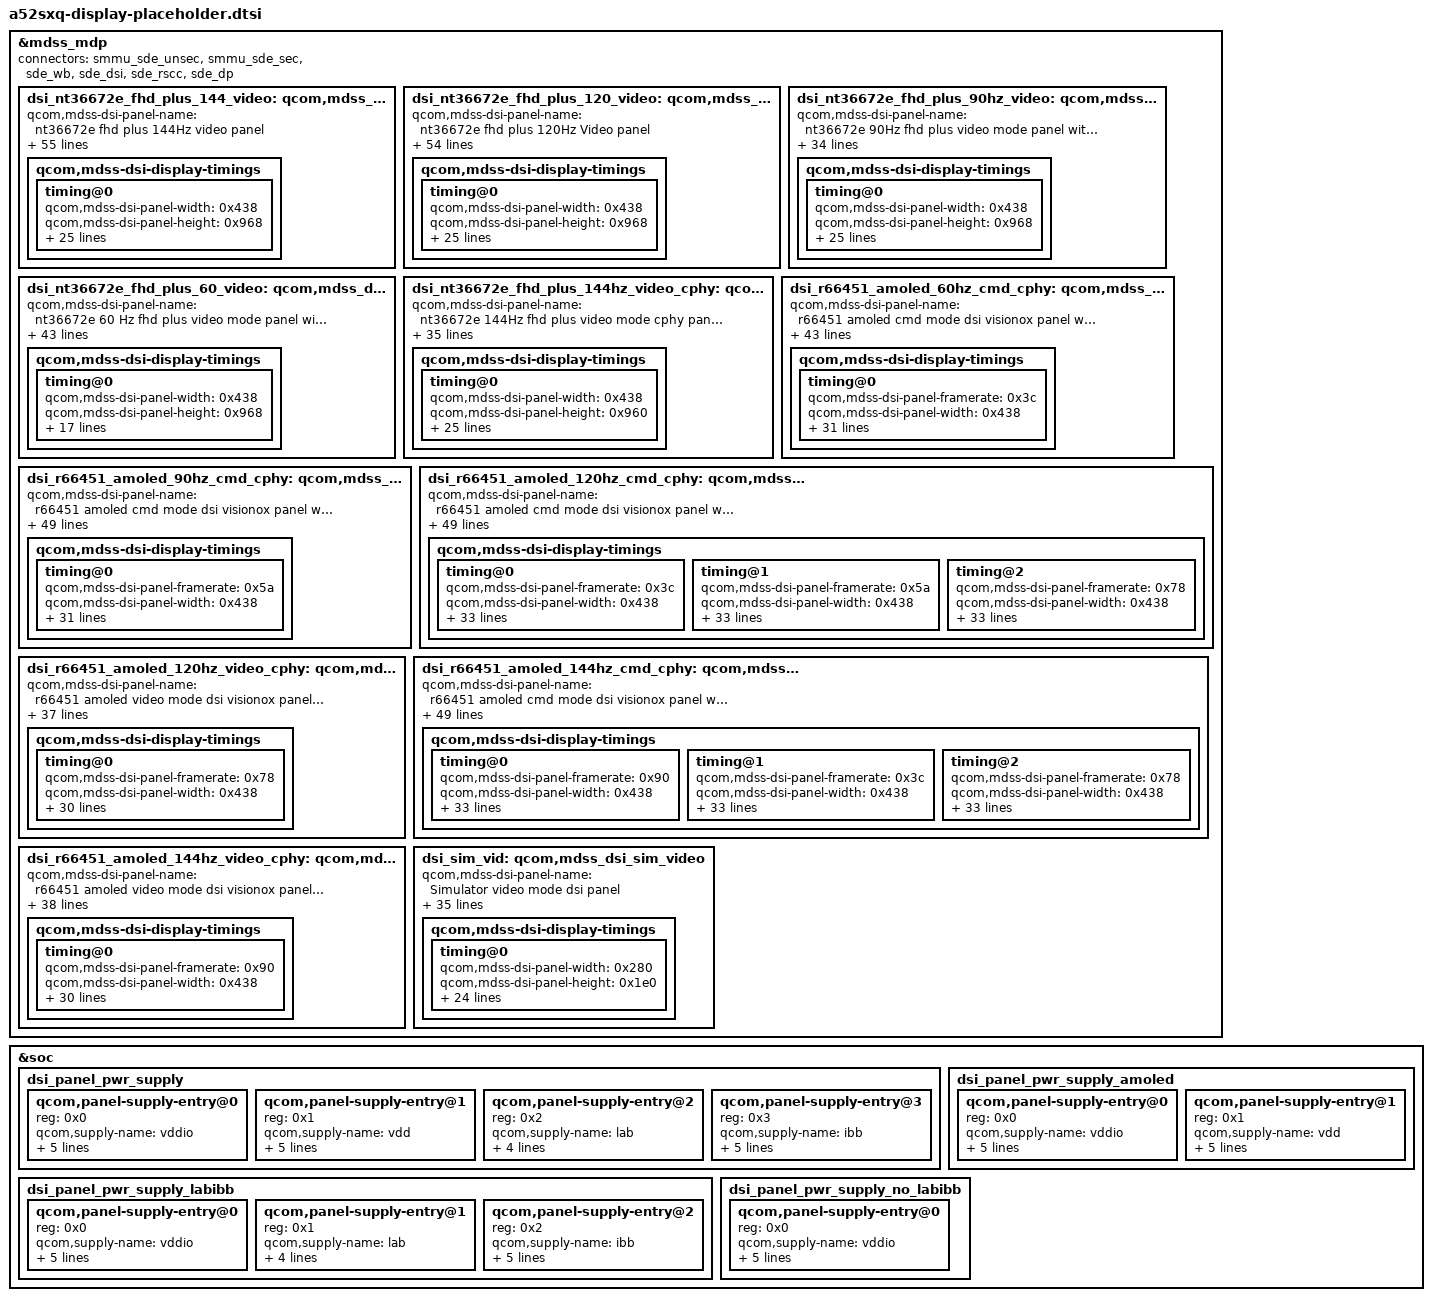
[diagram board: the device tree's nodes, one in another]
// SPDX-License-Identifier: GPL-2.0
/*
 * a52sxq board description for the Qualcomm 6.12 yupik base: display (owned by agent 'display': TODO-binding placeholder)
 * GENERATED by tools/gen.py from the phone's stock dtbo (5.4 bindings, values verbatim).
 * Do not edit: hand-written 6.12 changes live in a52sxq-bsp612-fixups.dtsi.
 */

&mdss_mdp {	/* TODO-binding: label not in the 6.12 base, placeholder */
	#cooling-cells = <0x2>;
	connectors = <&smmu_sde_unsec &smmu_sde_sec &sde_wb &sde_dsi &sde_rscc &sde_dp>;

	dsi_nt36672e_fhd_plus_144_video: qcom,mdss_dsi_nt36672e_fhd_plus_144_video {
		qcom,mdss-dsi-panel-name = "nt36672e fhd plus 144Hz video panel";
		qcom,mdss-dsi-panel-type = "dsi_video_mode";
		qcom,dsi-ctrl-num = <0x0>;
		qcom,dsi-phy-num = <0x0>;
		qcom,mdss-dsi-virtual-channel-id = <0x0>;
		qcom,mdss-dsi-stream = <0x0>;
		qcom,mdss-dsi-bpp = <0x18>;
		qcom,mdss-dsi-border-color = <0x0>;
		qcom,mdss-dsi-traffic-mode = "burst_mode";
		qcom,mdss-dsi-bllp-power-mode;
		qcom,mdss-dsi-bllp-eof-power-mode;
		qcom,mdss-dsi-lane-0-state;
		qcom,mdss-dsi-lane-1-state;
		qcom,mdss-dsi-lane-2-state;
		qcom,mdss-dsi-lane-3-state;
		qcom,mdss-dsi-dma-trigger = "trigger_sw";
		qcom,mdss-dsi-mdp-trigger = "none";
		qcom,mdss-dsi-reset-sequence = <0x1 0xa 0x0 0xa 0x1 0xa>;
		qcom,mdss-dsi-tx-eot-append;
		qcom,adjust-timer-wakeup-ms = <0x1>;
		qcom,mdss-dsi-panel-hdr-enabled;
		qcom,mdss-dsi-panel-hdr-color-primaries = <0x3a98 0x3e80 0x83d6 0x3db8 0x33c2 0x8692 0x1d4c 0xbb8>;
		qcom,mdss-dsi-panel-peak-brightness = <0x626b50>;
		qcom,mdss-dsi-panel-blackness-level = <0x1361>;
		qcom,dsi-select-clocks = "mux_byte_clk0", "mux_pixel_clk0", "src_byte_clk0", "src_pixel_clk0", "shadow_byte_clk0", "shadow_pixel_clk0";
		qcom,dsi-supported-dfps-list = <0x90 0x78 0x3c 0x30>;
		qcom,mdss-dsi-pan-enable-dynamic-fps;
		qcom,mdss-dsi-pan-fps-update = "dfps_immediate_porch_mode_vfp";
		qcom,mdss-dsi-qsync-min-refresh-rate = <0x30>;
		qcom,dsi-dyn-clk-enable;
		qcom,dsi-dyn-clk-list = <0x38d2d480 0x386dcf78 0x38a05200>;
		qcom,dsi-dyn-clk-type = "constant-fps-adjust-vfp";
		qcom,esd-check-enabled;
		qcom,mdss-dsi-panel-status-check-mode = "reg_read";
		qcom,mdss-dsi-panel-status-command = <0x6010001 0x10a>;
		qcom,mdss-dsi-panel-status-command-state = "dsi_lp_mode";
		qcom,mdss-dsi-panel-status-value = <0x9c>;
		qcom,mdss-dsi-panel-status-read-length = <0x1>;
		qcom,panel-supply-entries = <&dsi_panel_pwr_supply_labibb>;
		qcom,mdss-dsi-bl-pmic-control-type = "bl_ctrl_wled";
		qcom,mdss-dsi-bl-min-level = <0x1>;
		qcom,mdss-dsi-bl-max-level = <0xfff>;
		qcom,platform-reset-gpio = <&tlmm 0x2c 0x0>;

		qcom,mdss-dsi-display-timings {

			timing@0 {
				qcom,mdss-dsi-panel-width = <0x438>;
				qcom,mdss-dsi-panel-height = <0x968>;
				qcom,mdss-dsi-h-front-porch = <0x1e>;
				qcom,mdss-dsi-h-back-porch = <0x24>;
				qcom,mdss-dsi-h-pulse-width = <0x14>;
				qcom,mdss-dsi-h-sync-skew = <0x0>;
				qcom,mdss-dsi-v-back-porch = <0xa>;
				qcom,mdss-dsi-v-front-porch = <0x2e>;
				qcom,mdss-dsi-v-pulse-width = <0xa>;
				qcom,mdss-dsi-panel-framerate = <0x90>;
				qcom,mdss-dsi-on-command = [29 01 00 00 00 00 02 ff 10 29 01 00 00 00 00 02 fb 01 29 01 00 00 00 00 02 b0 00 29 01 00 00 00 00 11 c1 89 28 00 08 00 aa 02 0e 00 2b 00 07 0d b7 0c b7 29 01 00 00 00 00 03 c2 1b a0 29 01 00 00 00 00 02 e9 01 29 01 00 00 00 00 02 ff 20 29 01 00 00 00 00 02 fb 01 29 01 00 00 00 00 02 01 66 29 01 00 00 00 00 02 06 40 29 01 00 00 00 00 02 07 38 29 01 00 00 00 00 02 1b 01 29 01 00 00 00 00 02 2d 00 29 01 00 00 00 00 02 2f 83 29 01 00 00 00 00 02 69 91 29 01 00 00 00 00 02 95 d1 29 01 00 00 00 00 02 96 d1 29 01 00 00 00 00 02 f2 64 29 01 00 00 00 00 02 f4 64 29 01 00 00 00 00 02 f6 64 29 01 00 00 00 00 02 f8 64 29 01 00 00 00 00 02 ff 23 29 01 00 00 00 00 02 fb 01 29 01 00 00 00 00 02 00 00 29 01 00 00 00 00 02 04 05 29 01 00 00 00 00 02 05 2d 29 01 00 00 00 00 02 06 01 29 01 00 00 00 00 02 07 60 29 01 00 00 00 00 02 08 01 29 01 00 00 00 00 02 09 c7 29 01 00 00 00 00 02 11 01 29 01 00 00 00 00 02 12 95 29 01 00 00 00 00 02 15 68 29 01 00 00 00 00 02 16 0b 29 01 00 00 00 00 02 a0 00 29 01 00 00 00 00 02 30 ff 29 01 00 00 00 00 02 31 f0 29 01 00 00 00 00 02 32 eb 29 01 00 00 00 00 02 33 e5 29 01 00 00 00 00 02 34 dd 29 01 00 00 00 00 02 35 da 29 01 00 00 00 00 02 36 d5 29 01 00 00 00 00 02 37 d0 29 01 00 00 00 00 02 38 ce 29 01 00 00 00 00 02 39 cd 29 01 00 00 00 00 02 3a cd 29 01 00 00 00 00 02 3b cd 29 01 00 00 00 00 02 3d cb 29 01 00 00 00 00 02 3f cb 29 01 00 00 00 00 02 40 c6 29 01 00 00 00 00 02 41 bf 29 01 00 00 00 00 02 45 ff 29 01 00 00 00 00 02 46 f0 29 01 00 00 00 00 02 47 e8 29 01 00 00 00 00 02 48 ce 29 01 00 00 00 00 02 49 bc 29 01 00 00 00 00 02 4a b8 29 01 00 00 00 00 02 4b b5 29 01 00 00 00 00 02 4c b0 29 01 00 00 00 00 02 4d a8 29 01 00 00 00 00 02 4e a0 29 01 00 00 00 00 02 4f 9b 29 01 00 00 00 00 02 50 98 29 01 00 00 00 00 02 51 98 29 01 00 00 00 00 02 52 88 29 01 00 00 00 00 02 53 80 29 01 00 00 00 00 02 54 7f 29 01 00 00 00 00 02 58 ff 29 01 00 00 00 00 02 59 f6 29 01 00 00 00 00 02 5a ed 29 01 00 00 00 00 02 5b e6 29 01 00 00 00 00 02 5c df 29 01 00 00 00 00 02 5d d8 29 01 00 00 00 00 02 5e d3 29 01 00 00 00 00 02 5f ce 29 01 00 00 00 00 02 60 c9 29 01 00 00 00 00 02 61 c4 29 01 00 00 00 00 02 62 c1 29 01 00 00 00 00 02 63 be 29 01 00 00 00 00 02 64 bb 29 01 00 00 00 00 02 65 b8 29 01 00 00 00 00 02 66 b6 29 01 00 00 00 00 02 67 b5 29 01 00 00 00 00 02 ff 24 29 01 00 00 00 00 02 fb 01 29 01 00 00 00 00 02 01 0f 29 01 00 00 00 00 02 03 0c 29 01 00 00 00 00 02 05 1d 29 01 00 00 00 00 02 08 2f 29 01 00 00 00 00 02 09 2e 29 01 00 00 00 00 02 0a 2d 29 01 00 00 00 00 02 0b 2c 29 01 00 00 00 00 02 11 17 29 01 00 00 00 00 02 12 13 29 01 00 00 00 00 02 13 15 29 01 00 00 00 00 02 15 14 29 01 00 00 00 00 02 16 16 29 01 00 00 00 00 02 17 18 29 01 00 00 00 00 02 1b 01 29 01 00 00 00 00 02 1d 1d 29 01 00 00 00 00 02 20 2f 29 01 00 00 00 00 02 21 2e 29 01 00 00 00 00 02 22 2d 29 01 00 00 00 00 02 23 2c 29 01 00 00 00 00 02 29 17 29 01 00 00 00 00 02 2a 13 29 01 00 00 00 00 02 2b 15 29 01 00 00 00 00 02 2f 14 29 01 00 00 00 00 02 30 16 29 01 00 00 00 00 02 31 18 29 01 00 00 00 00 02 32 04 29 01 00 00 00 00 02 34 10 29 01 00 00 00 00 02 35 19 29 01 00 00 00 00 02 36 19 29 01 00 00 00 00 02 4d 11 29 01 00 00 00 00 02 4e 2b 29 01 00 00 00 00 02 4f 2b 29 01 00 00 00 00 02 53 2b 29 01 00 00 00 00 02 71 30 29 01 00 00 00 00 02 79 11 29 01 00 00 00 00 02 7a 82 29 01 00 00 00 00 02 7b 8b 29 01 00 00 00 00 02 7d 04 29 01 00 00 00 00 02 80 04 29 01 00 00 00 00 02 81 04 29 01 00 00 00 00 02 82 13 29 01 00 00 00 00 02 84 31 29 01 00 00 00 00 02 85 00 29 01 00 00 00 00 02 86 00 29 01 00 00 00 00 02 87 00 29 01 00 00 00 00 02 90 13 29 01 00 00 00 00 02 92 31 29 01 00 00 00 00 02 93 00 29 01 00 00 00 00 02 94 00 29 01 00 00 00 00 02 95 00 29 01 00 00 00 00 02 9c f4 29 01 00 00 00 00 02 9d 01 29 01 00 00 00 00 02 a0 0b 29 01 00 00 00 00 02 a2 0b 29 01 00 00 00 00 02 a3 02 29 01 00 00 00 00 02 a4 04 29 01 00 00 00 00 02 a5 04 29 01 00 00 00 00 02 c6 c0 29 01 00 00 00 00 02 c9 00 29 01 00 00 00 00 02 d9 80 29 01 00 00 00 00 02 e9 02 29 01 00 00 00 00 02 ff 25 29 01 00 00 00 00 02 fb 01 29 01 00 00 00 00 02 19 e4 29 01 00 00 00 00 02 21 00 29 01 00 00 00 00 02 66 d8 29 01 00 00 00 00 02 68 50 29 01 00 00 00 00 02 69 10 29 01 00 00 00 00 02 6b 00 29 01 00 00 00 00 02 6d 0d 29 01 00 00 00 00 02 6e 48 29 01 00 00 00 00 02 72 41 29 01 00 00 00 00 02 73 4a 29 01 00 00 00 00 02 74 d0 29 01 00 00 00 00 02 77 62 29 01 00 00 00 00 02 79 81 29 01 00 00 00 00 02 7d 03 29 01 00 00 00 00 02 7e 15 29 01 00 00 00 00 02 7f 00 29 01 00 00 00 00 02 84 4d 29 01 00 00 00 00 02 cf 00 29 01 00 00 00 00 02 d6 80 29 01 00 00 00 00 02 d7 80 29 01 00 00 00 00 02 ef 20 29 01 00 00 00 00 02 f0 84 29 01 00 00 00 00 02 ff 26 29 01 00 00 00 00 02 fb 01 29 01 00 00 00 00 02 80 05 29 01 00 00 00 00 02 81 0b 29 01 00 00 00 00 02 83 01 29 01 00 00 00 00 02 84 03 29 01 00 00 00 00 02 85 01 29 01 00 00 00 00 02 86 03 29 01 00 00 00 00 02 87 01 29 01 00 00 00 00 02 88 06 29 01 00 00 00 00 02 8a 1a 29 01 00 00 00 00 02 8b 11 29 01 00 00 00 00 02 8c 24 29 01 00 00 00 00 02 8e 42 29 01 00 00 00 00 02 8f 11 29 01 00 00 00 00 02 90 11 29 01 00 00 00 00 02 91 11 29 01 00 00 00 00 02 9a 80 29 01 00 00 00 00 02 9b 04 29 01 00 00 00 00 02 9c 00 29 01 00 00 00 00 02 9d 00 29 01 00 00 00 00 02 9e 00 29 01 00 00 00 00 02 ff 27 29 01 00 00 00 00 02 fb 01 29 01 00 00 00 00 02 01 68 29 01 00 00 00 00 02 20 81 29 01 00 00 00 00 02 21 30 29 01 00 00 00 00 02 25 81 29 01 00 00 00 00 02 26 67 29 01 00 00 00 00 02 6e 00 29 01 00 00 00 00 02 6f 00 29 01 00 00 00 00 02 70 00 29 01 00 00 00 00 02 71 00 29 01 00 00 00 00 02 72 00 29 01 00 00 00 00 02 75 00 29 01 00 00 00 00 02 76 00 29 01 00 00 00 00 02 77 00 29 01 00 00 00 00 02 7d 09 29 01 00 00 00 00 02 7e 67 29 01 00 00 00 00 02 80 23 29 01 00 00 00 00 02 82 09 29 01 00 00 00 00 02 83 67 29 01 00 00 00 00 02 88 01 29 01 00 00 00 00 02 89 10 29 01 00 00 00 00 02 a5 10 29 01 00 00 00 00 02 a6 23 29 01 00 00 00 00 02 a7 01 29 01 00 00 00 00 02 b6 40 29 01 00 00 00 00 02 ff 2a 29 01 00 00 00 00 02 fb 01 29 01 00 00 00 00 02 00 91 29 01 00 00 00 00 02 03 20 29 01 00 00 00 00 02 04 78 29 01 00 00 00 00 02 07 60 29 01 00 00 00 00 02 0a 70 29 01 00 00 00 00 02 0c 04 29 01 00 00 00 00 02 0d 40 29 01 00 00 00 00 02 0f 01 29 01 00 00 00 00 02 11 e0 29 01 00 00 00 00 02 15 0f 29 01 00 00 00 00 02 16 03 29 01 00 00 00 00 02 19 0e 29 01 00 00 00 00 02 1a d7 29 01 00 00 00 00 02 1b 14 29 01 00 00 00 00 02 1d 2e 29 01 00 00 00 00 02 1e 33 29 01 00 00 00 00 02 1f 33 29 01 00 00 00 00 02 20 33 29 01 00 00 00 00 02 28 fd 29 01 00 00 00 00 02 29 0d 29 01 00 00 00 00 02 2a b7 29 01 00 00 00 00 02 2d 09 29 01 00 00 00 00 02 2f 02 29 01 00 00 00 00 02 30 47 29 01 00 00 00 00 02 33 d8 29 01 00 00 00 00 02 34 ff 29 01 00 00 00 00 02 35 40 29 01 00 00 00 00 02 36 b8 29 01 00 00 00 00 02 37 f9 29 01 00 00 00 00 02 38 45 29 01 00 00 00 00 02 39 b3 29 01 00 00 00 00 02 3a 47 29 01 00 00 00 00 02 4a f0 29 01 00 00 00 00 02 ff 20 29 01 00 00 00 00 02 fb 01 29 01 00 00 00 00 11 b0 00 e2 00 e9 00 f6 01 01 01 0c 01 15 01 20 01 28 29 01 00 00 00 00 11 b1 01 33 01 51 01 6e 01 9a 01 c0 01 fd 02 34 02 35 29 01 00 00 00 00 11 b2 02 6b 02 a9 02 d1 03 04 03 25 03 51 03 5f 03 6d 29 01 00 00 00 00 0f b3 03 7d 03 90 03 a7 03 bb 03 d4 03 d8 00 00 29 01 00 00 00 00 11 b4 00 aa 00 b3 00 c4 00 d4 00 e2 00 f0 00 fc 01 08 29 01 00 00 00 00 11 b5 01 12 01 39 01 58 01 8c 01 b5 01 f7 02 30 02 31 29 01 00 00 00 00 11 b6 02 68 02 a6 02 ce 03 01 03 23 03 4e 03 5c 03 6a 29 01 00 00 00 00 0f b7 03 7b 03 8e 03 a5 03 bb 03 d4 03 d8 00 00 29 01 00 00 00 00 11 b8 00 00 00 20 00 47 00 65 00 85 00 99 00 ad 00 c0 29 01 00 00 00 00 11 b9 00 d2 01 06 01 30 01 70 01 9f 01 e8 02 25 02 26 29 01 00 00 00 00 11 ba 02 5f 02 9f 02 c7 02 fd 03 20 03 52 03 63 03 67 29 01 00 00 00 00 0f bb 03 78 03 8b 03 a3 03 b9 03 d4 03 d8 00 00 29 01 00 00 00 00 02 ff 21 29 01 00 00 00 00 02 fb 01 29 01 00 00 00 00 11 b0 00 e2 00 e9 00 f6 01 01 01 0c 01 15 01 20 01 28 29 01 00 00 00 00 11 b1 01 33 01 51 01 6e 01 9a 01 c0 01 fd 02 34 02 35 29 01 00 00 00 00 11 b2 02 6b 02 a9 02 d1 03 04 03 25 03 51 03 5f 03 6d 29 01 00 00 00 00 0f b3 03 7d 03 90 03 a7 03 bb 03 d4 03 d8 00 00 29 01 00 00 00 00 11 b4 00 aa 00 b3 00 c4 00 d4 00 e2 00 f0 00 fc 01 08 29 01 00 00 00 00 11 b5 01 12 01 39 01 58 01 8c 01 b5 01 f7 02 30 02 31 29 01 00 00 00 00 11 b6 02 68 02 a6 02 ce 03 01 03 23 03 4e 03 5c 03 6a 29 01 00 00 00 00 0f b7 03 7b 03 8e 03 a5 03 bb 03 d4 03 d8 00 00 29 01 00 00 00 00 11 b8 00 00 00 20 00 47 00 65 00 85 00 99 00 ad 00 c0 29 01 00 00 00 00 11 b9 00 d2 01 06 01 30 01 70 01 9f 01 e8 02 25 02 26 29 01 00 00 00 00 11 ba 02 5f 02 9f 02 c7 02 fd 03 20 03 52 03 63 03 67 29 01 00 00 00 00 0f bb 03 78 03 8b 03 a3 03 b9 03 d4 03 d8 00 00 29 01 00 00 00 00 02 ff c0 29 01 00 00 00 00 02 fb 01 29 01 00 00 00 00 02 9c 11 29 01 00 00 00 00 02 9d 11 29 01 00 00 00 00 02 ff f0 29 01 00 00 00 00 02 fb 01 29 01 00 00 00 00 02 5a 00 29 01 00 00 00 00 02 9f 0c 29 01 00 00 00 00 02 ff d0 29 01 00 00 00 00 02 fb 01 29 01 00 00 00 00 02 53 22 29 01 00 00 00 00 02 54 02 29 01 00 00 00 00 02 ff e0 29 01 00 00 00 00 02 fb 01 29 01 00 00 00 00 02 35 82 29 01 00 00 00 00 02 ff 10 29 01 00 00 00 00 02 fb 01 15 01 00 00 00 00 02 35 01 05 01 00 00 c8 00 01 11 05 01 00 00 96 00 01 29];
				qcom,mdss-dsi-on-command-state = "dsi_lp_mode";
				qcom,mdss-dsi-off-command = <0x5010000 0x10000128 0x5010000 0x32000110>;
				qcom,mdss-dsi-off-command-state = "dsi_lp_mode";
				qcom,compression-mode = "dsc";
				qcom,mdss-dsc-slice-height = <0x8>;
				qcom,mdss-dsc-slice-width = <0x21c>;
				qcom,mdss-dsc-slice-per-pkt = <0x1>;
				qcom,mdss-dsc-bit-per-component = <0x8>;
				qcom,mdss-dsc-bit-per-pixel = <0x8>;
				qcom,mdss-dsc-block-prediction-enable;
				qcom,mdss-dsi-panel-phy-timings = [00 20 08 08 24 23 08 08 08 02 04 00 1c 18];
				qcom,display-topology = <0x1 0x1 0x1>;
				qcom,default-topology-index = <0x0>;
			};
		};
	};

	dsi_nt36672e_fhd_plus_120_video: qcom,mdss_dsi_nt36672e_fhd_plus_120_video {
		qcom,mdss-dsi-panel-name = "nt36672e fhd plus 120Hz Video panel";
		qcom,mdss-dsi-panel-type = "dsi_video_mode";
		qcom,dsi-ctrl-num = <0x0>;
		qcom,dsi-phy-num = <0x0>;
		qcom,mdss-dsi-virtual-channel-id = <0x0>;
		qcom,mdss-dsi-stream = <0x0>;
		qcom,mdss-dsi-bpp = <0x18>;
		qcom,mdss-dsi-border-color = <0x0>;
		qcom,mdss-dsi-traffic-mode = "burst_mode";
		qcom,mdss-dsi-bllp-power-mode;
		qcom,mdss-dsi-bllp-eof-power-mode;
		qcom,mdss-dsi-lane-0-state;
		qcom,mdss-dsi-lane-1-state;
		qcom,mdss-dsi-lane-2-state;
		qcom,mdss-dsi-lane-3-state;
		qcom,mdss-dsi-dma-trigger = "trigger_sw";
		qcom,mdss-dsi-mdp-trigger = "none";
		qcom,mdss-dsi-reset-sequence = <0x1 0xa 0x0 0xa 0x1 0xa>;
		qcom,mdss-dsi-tx-eot-append;
		qcom,adjust-timer-wakeup-ms = <0x1>;
		qcom,mdss-dsi-panel-hdr-enabled;
		qcom,mdss-dsi-panel-hdr-color-primaries = <0x3a98 0x3e80 0x83d6 0x3db8 0x33c2 0x8692 0x1d4c 0xbb8>;
		qcom,mdss-dsi-panel-peak-brightness = <0x626b50>;
		qcom,mdss-dsi-panel-blackness-level = <0x1361>;
		qcom,dsi-select-clocks = "mux_byte_clk0", "mux_pixel_clk0", "src_byte_clk0", "src_pixel_clk0", "shadow_byte_clk0", "shadow_pixel_clk0";
		qcom,dsi-supported-dfps-list = <0x78 0x3c 0x30>;
		qcom,mdss-dsi-pan-enable-dynamic-fps;
		qcom,mdss-dsi-pan-fps-update = "dfps_immediate_porch_mode_vfp";
		qcom,mdss-dsi-qsync-min-refresh-rate = <0x30>;
		qcom,dsi-dyn-clk-enable;
		qcom,dsi-dyn-clk-list = <0x35b92b40 0x35468f28 0x357fdd38>;
		qcom,dsi-dyn-clk-type = "constant-fps-adjust-vfp";
		qcom,esd-check-enabled;
		qcom,mdss-dsi-panel-status-check-mode = "reg_read";
		qcom,mdss-dsi-panel-status-command = <0x6010001 0x10a>;
		qcom,mdss-dsi-panel-status-command-state = "dsi_lp_mode";
		qcom,mdss-dsi-panel-status-value = <0x9c>;
		qcom,mdss-dsi-panel-status-read-length = <0x1>;
		qcom,panel-supply-entries = <&dsi_panel_pwr_supply_labibb>;
		qcom,mdss-dsi-bl-pmic-control-type = "bl_ctrl_wled";
		qcom,mdss-dsi-bl-min-level = <0x1>;
		qcom,mdss-dsi-bl-max-level = <0xfff>;
		qcom,platform-reset-gpio = <&tlmm 0x2c 0x0>;

		qcom,mdss-dsi-display-timings {

			timing@0 {
				qcom,mdss-dsi-panel-width = <0x438>;
				qcom,mdss-dsi-panel-height = <0x968>;
				qcom,mdss-dsi-h-front-porch = <0x4c>;
				qcom,mdss-dsi-h-back-porch = <0x3c>;
				qcom,mdss-dsi-h-pulse-width = <0xa>;
				qcom,mdss-dsi-h-sync-skew = <0x0>;
				qcom,mdss-dsi-v-back-porch = <0xa>;
				qcom,mdss-dsi-v-front-porch = <0x2e>;
				qcom,mdss-dsi-v-pulse-width = <0xa>;
				qcom,mdss-dsi-panel-framerate = <0x78>;
				qcom,mdss-dsi-on-command = [15 01 00 00 00 00 02 fb 01 15 01 00 00 00 00 02 b0 00 15 01 00 00 00 00 02 c0 03 39 01 00 00 00 00 11 c1 89 28 00 08 00 aa 02 0e 00 2b 00 07 0d b7 0c b7 39 01 00 00 00 00 03 c2 1b a0 15 01 00 00 00 00 02 ff 20 15 01 00 00 00 00 02 fb 01 15 01 00 00 00 00 02 01 66 15 01 00 00 00 00 02 06 40 15 01 00 00 00 00 02 07 38 15 01 00 00 00 00 02 2f 83 15 01 00 00 00 00 02 69 91 15 01 00 00 00 00 02 95 d1 15 01 00 00 00 00 02 96 d1 15 01 00 00 00 00 02 f2 64 15 01 00 00 00 00 02 f4 64 15 01 00 00 00 00 02 f6 64 15 01 00 00 00 00 02 f8 64 15 01 00 00 00 00 02 89 1c 15 01 00 00 00 00 02 8a 1c 15 01 00 00 00 00 02 8b 1c 15 01 00 00 00 00 02 8c 1c 15 01 00 00 00 00 02 ff 24 15 01 00 00 00 00 02 fb 01 15 01 00 00 00 00 02 01 0f 15 01 00 00 00 00 02 03 0c 15 01 00 00 00 00 02 05 1d 15 01 00 00 00 00 02 08 2f 15 01 00 00 00 00 02 09 2e 15 01 00 00 00 00 02 0a 2d 15 01 00 00 00 00 02 0b 2c 15 01 00 00 00 00 02 11 17 15 01 00 00 00 00 02 12 13 15 01 00 00 00 00 02 13 15 15 01 00 00 00 00 02 15 14 15 01 00 00 00 00 02 16 16 15 01 00 00 00 00 02 17 18 15 01 00 00 00 00 02 1b 01 15 01 00 00 00 00 02 1d 1d 15 01 00 00 00 00 02 20 2f 15 01 00 00 00 00 02 21 2e 15 01 00 00 00 00 02 22 2d 15 01 00 00 00 00 02 23 2c 15 01 00 00 00 00 02 29 17 15 01 00 00 00 00 02 2a 13 15 01 00 00 00 00 02 2b 15 15 01 00 00 00 00 02 2f 14 15 01 00 00 00 00 02 30 16 15 01 00 00 00 00 02 31 18 15 01 00 00 00 00 02 32 04 15 01 00 00 00 00 02 34 10 15 01 00 00 00 00 02 35 1f 15 01 00 00 00 00 02 36 1f 15 01 00 00 00 00 02 4d 14 15 01 00 00 00 00 02 4e 36 15 01 00 00 00 00 02 4f 36 15 01 00 00 00 00 02 53 36 15 01 00 00 00 00 02 71 30 15 01 00 00 00 00 02 79 11 15 01 00 00 00 00 02 7a 82 15 01 00 00 00 00 02 7b 8f 15 01 00 00 00 00 02 7d 04 15 01 00 00 00 00 02 80 04 15 01 00 00 00 00 02 81 04 15 01 00 00 00 00 02 82 13 15 01 00 00 00 00 02 84 31 15 01 00 00 00 00 02 85 00 15 01 00 00 00 00 02 86 00 15 01 00 00 00 00 02 87 00 15 01 00 00 00 00 02 90 13 15 01 00 00 00 00 02 92 31 15 01 00 00 00 00 02 93 00 15 01 00 00 00 00 02 94 00 15 01 00 00 00 00 02 95 00 15 01 00 00 00 00 02 9c f4 15 01 00 00 00 00 02 9d 01 15 01 00 00 00 00 02 a0 0f 15 01 00 00 00 00 02 a2 0f 15 01 00 00 00 00 02 a3 02 15 01 00 00 00 00 02 a4 04 15 01 00 00 00 00 02 a5 04 15 01 00 00 00 00 02 c4 40 15 01 00 00 00 00 02 c6 c0 15 01 00 00 00 00 02 c9 00 15 01 00 00 00 00 02 d9 80 15 01 00 00 00 00 02 e9 02 15 01 00 00 00 00 02 ff 25 15 01 00 00 00 00 02 fb 01 15 01 00 00 00 00 02 19 e4 15 01 00 00 00 00 02 21 40 15 01 00 00 00 00 02 66 d8 15 01 00 00 00 00 02 68 50 15 01 00 00 00 00 02 69 10 15 01 00 00 00 00 02 6b 00 15 01 00 00 00 00 02 6d 0d 15 01 00 00 00 00 02 6e 48 15 01 00 00 00 00 02 72 41 15 01 00 00 00 00 02 73 4a 15 01 00 00 00 00 02 74 d0 15 01 00 00 00 00 02 77 62 15 01 00 00 00 00 02 79 81 15 01 00 00 00 00 02 7d 03 15 01 00 00 00 00 02 7e 15 15 01 00 00 00 00 02 7f 00 15 01 00 00 00 00 02 84 4d 15 01 00 00 00 00 02 cf 80 15 01 00 00 00 00 02 d6 80 15 01 00 00 00 00 02 d7 80 15 01 00 00 00 00 02 ef 20 15 01 00 00 00 00 02 f0 84 15 01 00 00 00 00 02 ff 26 15 01 00 00 00 00 02 fb 01 15 01 00 00 00 00 02 80 05 15 01 00 00 00 00 02 81 0f 15 01 00 00 00 00 02 83 01 15 01 00 00 00 00 02 84 03 15 01 00 00 00 00 02 85 01 15 01 00 00 00 00 02 86 03 15 01 00 00 00 00 02 87 01 15 01 00 00 00 00 02 88 05 15 01 00 00 00 00 02 8a 1a 15 01 00 00 00 00 02 8b 11 15 01 00 00 00 00 02 8c 24 15 01 00 00 00 00 02 8e 42 15 01 00 00 00 00 02 8f 11 15 01 00 00 00 00 02 90 11 15 01 00 00 00 00 02 91 11 15 01 00 00 00 00 02 9a 80 15 01 00 00 00 00 02 9b 04 15 01 00 00 00 00 02 9c 00 15 01 00 00 00 00 02 9d 00 15 01 00 00 00 00 02 9e 00 15 01 00 00 00 00 02 ff 27 15 01 00 00 00 00 02 fb 01 15 01 00 00 00 00 02 01 68 15 01 00 00 00 00 02 20 81 15 01 00 00 00 00 02 21 6a 15 01 00 00 00 00 02 25 81 15 01 00 00 00 00 02 26 94 15 01 00 00 00 00 02 6e 00 15 01 00 00 00 00 02 6f 00 15 01 00 00 00 00 02 70 00 15 01 00 00 00 00 02 71 00 15 01 00 00 00 00 02 72 00 15 01 00 00 00 00 02 75 00 15 01 00 00 00 00 02 76 00 15 01 00 00 00 00 02 77 00 15 01 00 00 00 00 02 7d 09 15 01 00 00 00 00 02 7e 67 15 01 00 00 00 00 02 80 23 15 01 00 00 00 00 02 82 09 15 01 00 00 00 00 02 83 67 15 01 00 00 00 00 02 88 01 15 01 00 00 00 00 02 89 10 15 01 00 00 00 00 02 a5 10 15 01 00 00 00 00 02 a6 23 15 01 00 00 00 00 02 a7 01 15 01 00 00 00 00 02 b6 40 15 01 00 00 00 00 02 ff 2a 15 01 00 00 00 00 02 fb 01 15 01 00 00 00 00 02 00 91 15 01 00 00 00 00 02 03 20 15 01 00 00 00 00 02 07 50 15 01 00 00 00 00 02 0a 70 15 01 00 00 00 00 02 0c 04 15 01 00 00 00 00 02 0d 40 15 01 00 00 00 00 02 0f 01 15 01 00 00 00 00 02 11 e0 15 01 00 00 00 00 02 15 0f 15 01 00 00 00 00 02 16 a4 15 01 00 00 00 00 02 19 0f 15 01 00 00 00 00 02 1a 78 15 01 00 00 00 00 02 1b 23 15 01 00 00 00 00 02 1d 36 15 01 00 00 00 00 02 1e 3e 15 01 00 00 00 00 02 1f 3e 15 01 00 00 00 00 02 20 3e 15 01 00 00 00 00 02 28 fd 15 01 00 00 00 00 02 29 12 15 01 00 00 00 00 02 2a e1 15 01 00 00 00 00 02 2d 0a 15 01 00 00 00 00 02 30 49 15 01 00 00 00 00 02 33 96 15 01 00 00 00 00 02 34 ff 15 01 00 00 00 00 02 35 40 15 01 00 00 00 00 02 36 de 15 01 00 00 00 00 02 37 f9 15 01 00 00 00 00 02 38 45 15 01 00 00 00 00 02 39 d9 15 01 00 00 00 00 02 3a 49 15 01 00 00 00 00 02 4a f0 15 01 00 00 00 00 02 ff 20 15 01 00 00 00 00 02 fb 01 39 01 00 00 00 00 11 b0 00 00 00 17 00 46 00 63 00 81 00 96 00 ab 00 bd 39 01 00 00 00 00 11 b1 00 cf 01 03 01 2f 01 6e 01 9d 01 e7 02 22 02 24 39 01 00 00 00 00 11 b2 02 5d 02 9b 02 c4 02 f9 03 1b 03 48 03 56 03 65 39 01 00 00 00 00 0f b3 03 75 03 87 03 9b 03 b1 03 ca 03 d7 00 00 39 01 00 00 00 00 11 b4 00 00 00 19 00 4b 00 69 00 87 00 9c 00 b2 00 c3 39 01 00 00 00 00 11 b5 00 d5 01 0b 01 35 01 73 01 a3 01 ec 02 27 02 29 39 01 00 00 00 00 11 b6 02 60 02 9f 02 c7 02 fb 03 1d 03 4c 03 5a 03 69 39 01 00 00 00 00 0f b7 03 7a 03 8c 03 a0 03 b5 03 cb 03 d7 00 00 39 01 00 00 00 00 11 b8 00 00 00 19 00 4d 00 6a 00 87 00 9c 00 b1 00 c2 39 01 00 00 00 00 11 b9 00 d3 01 08 01 32 01 70 01 9f 01 e8 02 23 02 25 39 01 00 00 00 00 11 ba 02 5c 02 9b 02 c3 02 f8 03 1a 03 4c 03 5b 03 6b 39 01 00 00 00 00 0f bb 03 7d 03 92 03 a7 03 bb 03 ce 03 d7 00 00 15 01 00 00 00 00 02 ff 21 15 01 00 00 00 00 02 fb 01 39 01 00 00 00 00 11 b0 00 00 00 17 00 46 00 63 00 81 00 96 00 ab 00 bd 39 01 00 00 00 00 11 b1 00 cf 01 03 01 2f 01 6e 01 9d 01 e7 02 22 02 24 39 01 00 00 00 00 11 b2 02 5d 02 9b 02 c4 02 f9 03 1b 03 48 03 56 03 65 39 01 00 00 00 00 0f b3 03 75 03 87 03 9b 03 b1 03 ca 03 d7 00 00 39 01 00 00 00 00 11 b4 00 00 00 19 00 4b 00 69 00 87 00 9c 00 b2 00 c3 39 01 00 00 00 00 11 b5 00 d5 01 0b 01 35 01 73 01 a3 01 ec 02 27 02 29 39 01 00 00 00 00 11 b6 02 60 02 9f 02 c7 02 fb 03 1d 03 4c 03 5a 03 69 39 01 00 00 00 00 0f b7 03 7a 03 8c 03 a0 03 b5 03 cb 03 d7 00 00 39 01 00 00 00 00 11 b8 00 00 00 19 00 4d 00 6a 00 87 00 9c 00 b1 00 c2 39 01 00 00 00 00 11 b9 00 d3 01 08 01 32 01 70 01 9f 01 e8 02 23 02 25 39 01 00 00 00 00 11 ba 02 5c 02 9b 02 c3 02 f8 03 1a 03 4c 03 5b 03 6b 39 01 00 00 00 00 0f bb 03 7d 03 92 03 a7 03 bb 03 ce 03 d7 00 00 15 01 00 00 00 00 02 ff 10 15 01 00 00 00 00 02 ff f0 15 01 00 00 00 00 02 fb 01 15 01 00 00 00 00 02 5a 00 15 01 00 00 00 00 02 ff 10 15 01 00 00 00 00 02 ff 10 15 01 00 00 00 00 02 fb 01 15 01 00 00 00 00 02 51 ff 15 01 00 00 00 00 02 53 2c 15 01 00 00 00 00 02 55 01 05 01 00 00 c8 00 01 11 05 01 00 00 96 00 01 29];
				qcom,mdss-dsi-on-command-state = "dsi_lp_mode";
				qcom,mdss-dsi-off-command = <0x5010000 0x10000128 0x5010000 0x32000110>;
				qcom,mdss-dsi-off-command-state = "dsi_lp_mode";
				qcom,compression-mode = "dsc";
				qcom,mdss-dsc-slice-height = <0x8>;
				qcom,mdss-dsc-slice-width = <0x21c>;
				qcom,mdss-dsc-slice-per-pkt = <0x1>;
				qcom,mdss-dsc-bit-per-component = <0x8>;
				qcom,mdss-dsc-bit-per-pixel = <0x8>;
				qcom,mdss-dsc-block-prediction-enable;
				qcom,mdss-dsi-panel-phy-timings = [00 1e 08 08 24 22 08 08 08 02 04 00 1b 18];
				qcom,display-topology = <0x1 0x1 0x1>;
				qcom,default-topology-index = <0x0>;
			};
		};
	};

	dsi_nt36672e_fhd_plus_90hz_video: qcom,mdss_dsi_nt36672e_fhd_plus_90hz_video {
		qcom,mdss-dsi-panel-name = "nt36672e 90Hz fhd plus video mode panel with DSC";
		qcom,mdss-dsi-panel-type = "dsi_video_mode";
		qcom,dsi-ctrl-num = <0x0>;
		qcom,dsi-phy-num = <0x0>;
		qcom,mdss-dsi-virtual-channel-id = <0x0>;
		qcom,mdss-dsi-stream = <0x0>;
		qcom,mdss-dsi-bpp = <0x18>;
		qcom,mdss-dsi-border-color = <0x0>;
		qcom,mdss-dsi-traffic-mode = "burst_mode";
		qcom,mdss-dsi-bllp-power-mode;
		qcom,mdss-dsi-bllp-eof-power-mode;
		qcom,mdss-dsi-lane-0-state;
		qcom,mdss-dsi-lane-1-state;
		qcom,mdss-dsi-lane-2-state;
		qcom,mdss-dsi-lane-3-state;
		qcom,mdss-dsi-dma-trigger = "trigger_sw";
		qcom,mdss-dsi-mdp-trigger = "none";
		qcom,mdss-dsi-reset-sequence = <0x1 0xa 0x0 0xa 0x1 0xa>;
		qcom,mdss-dsi-tx-eot-append;
		qcom,adjust-timer-wakeup-ms = <0x1>;
		qcom,mdss-dsi-panel-hdr-enabled;
		qcom,mdss-dsi-panel-hdr-color-primaries = <0x9858 0x3e80 0x83d6 0x9b78 0x33c2 0x8692 0x1d4c 0xbb8>;
		qcom,mdss-dsi-panel-peak-brightness = <0x626b50>;
		qcom,mdss-dsi-panel-blackness-level = <0x1361>;
		qcom,dsi-select-clocks = "mux_byte_clk0", "mux_pixel_clk0";
		qcom,panel-supply-entries = <&dsi_panel_pwr_supply_labibb>;
		qcom,mdss-dsi-bl-pmic-control-type = "bl_ctrl_wled";
		qcom,mdss-dsi-bl-min-level = <0x1>;
		qcom,mdss-dsi-bl-max-level = <0xfff>;
		qcom,platform-reset-gpio = <&tlmm 0x2c 0x0>;

		qcom,mdss-dsi-display-timings {

			timing@0 {
				qcom,mdss-dsi-panel-width = <0x438>;
				qcom,mdss-dsi-panel-height = <0x968>;
				qcom,mdss-dsi-h-front-porch = <0x4c>;
				qcom,mdss-dsi-h-back-porch = <0x44>;
				qcom,mdss-dsi-h-pulse-width = <0xa>;
				qcom,mdss-dsi-h-sync-skew = <0x0>;
				qcom,mdss-dsi-v-back-porch = <0xa>;
				qcom,mdss-dsi-v-front-porch = <0x2e>;
				qcom,mdss-dsi-v-pulse-width = <0xa>;
				qcom,mdss-dsi-panel-framerate = <0x5a>;
				qcom,mdss-dsi-on-command = [39 01 00 00 00 00 02 ff 10 39 01 00 00 00 00 02 fb 01 39 01 00 00 00 00 02 b0 00 39 01 00 00 00 00 02 c0 03 39 01 00 00 00 00 11 c1 89 28 00 08 00 aa 02 0e 00 2b 00 07 0d b7 0c b7 39 01 00 00 00 00 03 c2 1b a0 39 01 00 00 00 00 02 ff 20 39 01 00 00 00 00 02 fb 01 39 01 00 00 00 00 02 01 66 39 01 00 00 00 00 02 06 40 39 01 00 00 00 00 02 07 38 39 01 00 00 00 00 02 18 66 39 01 00 00 00 00 02 1b 01 39 01 00 00 00 00 02 5c 90 39 01 00 00 00 00 02 5e aa 39 01 00 00 00 00 02 69 91 39 01 00 00 00 00 02 89 0d 39 01 00 00 00 00 02 8a 0d 39 01 00 00 00 00 02 8d 0d 39 01 00 00 00 00 02 8e 0d 39 01 00 00 00 00 02 8f 0d 39 01 00 00 00 00 02 91 0d 39 01 00 00 00 00 02 95 d1 39 01 00 00 00 00 02 96 d1 39 01 00 00 00 00 02 f2 65 39 01 00 00 00 00 02 f3 64 39 01 00 00 00 00 02 f4 65 39 01 00 00 00 00 02 f5 64 39 01 00 00 00 00 02 f6 65 39 01 00 00 00 00 02 f7 64 39 01 00 00 00 00 02 f8 65 39 01 00 00 00 00 02 f9 64 39 01 00 00 00 00 02 ff 24 39 01 00 00 00 00 02 fb 01 39 01 00 00 00 00 02 01 0f 39 01 00 00 00 00 02 03 0c 39 01 00 00 00 00 02 05 1d 39 01 00 00 00 00 02 08 2f 39 01 00 00 00 00 02 09 2e 39 01 00 00 00 00 02 0a 2d 39 01 00 00 00 00 02 0b 2c 39 01 00 00 00 00 02 11 17 39 01 00 00 00 00 02 12 13 39 01 00 00 00 00 02 13 15 39 01 00 00 00 00 02 15 14 39 01 00 00 00 00 02 16 16 39 01 00 00 00 00 02 17 18 39 01 00 00 00 00 02 1b 01 39 01 00 00 00 00 02 1d 1d 39 01 00 00 00 00 02 20 2f 39 01 00 00 00 00 02 21 2e 39 01 00 00 00 00 02 22 2d 39 01 00 00 00 00 02 23 2c 39 01 00 00 00 00 02 29 17 39 01 00 00 00 00 02 2a 13 39 01 00 00 00 00 02 2b 15 39 01 00 00 00 00 02 2f 14 39 01 00 00 00 00 02 30 16 39 01 00 00 00 00 02 31 18 39 01 00 00 00 00 02 32 04 39 01 00 00 00 00 02 34 10 39 01 00 00 00 00 02 35 1f 39 01 00 00 00 00 02 36 1f 39 01 00 00 00 00 02 4d 19 39 01 00 00 00 00 02 4e 45 39 01 00 00 00 00 02 4f 45 39 01 00 00 00 00 02 53 45 39 01 00 00 00 00 02 71 30 39 01 00 00 00 00 02 79 11 39 01 00 00 00 00 02 7a 82 39 01 00 00 00 00 02 7b 94 39 01 00 00 00 00 02 7d 04 39 01 00 00 00 00 02 80 04 39 01 00 00 00 00 02 81 04 39 01 00 00 00 00 02 82 13 39 01 00 00 00 00 02 84 31 39 01 00 00 00 00 02 85 00 39 01 00 00 00 00 02 86 00 39 01 00 00 00 00 02 87 00 39 01 00 00 00 00 02 90 13 39 01 00 00 00 00 02 92 31 39 01 00 00 00 00 02 93 00 39 01 00 00 00 00 02 94 00 39 01 00 00 00 00 02 95 00 39 01 00 00 00 00 02 9c f4 39 01 00 00 00 00 02 9d 01 39 01 00 00 00 00 02 a0 14 39 01 00 00 00 00 02 a2 14 39 01 00 00 00 00 02 a3 02 39 01 00 00 00 00 02 a4 04 39 01 00 00 00 00 02 a5 04 39 01 00 00 00 00 02 c4 40 39 01 00 00 00 00 02 c6 c0 39 01 00 00 00 00 02 c9 00 39 01 00 00 00 00 02 d9 80 39 01 00 00 00 00 02 e9 02 39 01 00 00 00 00 02 ff 25 39 01 00 00 00 00 02 fb 01 39 01 00 00 00 00 02 0f 1b 39 01 00 00 00 00 02 19 e4 39 01 00 00 00 00 02 21 40 39 01 00 00 00 00 02 66 d8 39 01 00 00 00 00 02 68 50 39 01 00 00 00 00 02 69 10 39 01 00 00 00 00 02 6b 00 39 01 00 00 00 00 02 6d 0d 39 01 00 00 00 00 02 6e 48 39 01 00 00 00 00 02 72 41 39 01 00 00 00 00 02 73 4a 39 01 00 00 00 00 02 74 d0 39 01 00 00 00 00 02 77 62 39 01 00 00 00 00 02 79 7f 39 01 00 00 00 00 02 7d 40 39 01 00 00 00 00 02 7f 00 39 01 00 00 00 00 02 80 04 39 01 00 00 00 00 02 84 0d 39 01 00 00 00 00 02 cf 80 39 01 00 00 00 00 02 d6 80 39 01 00 00 00 00 02 d7 80 39 01 00 00 00 00 02 ef 20 39 01 00 00 00 00 02 f0 84 39 01 00 00 00 00 02 ff 26 39 01 00 00 00 00 02 fb 01 39 01 00 00 00 00 02 15 04 39 01 00 00 00 00 02 81 14 39 01 00 00 00 00 02 83 02 39 01 00 00 00 00 02 84 03 39 01 00 00 00 00 02 85 01 39 01 00 00 00 00 02 86 03 39 01 00 00 00 00 02 87 01 39 01 00 00 00 00 02 88 06 39 01 00 00 00 00 02 8a 1a 39 01 00 00 00 00 02 8b 11 39 01 00 00 00 00 02 8c 24 39 01 00 00 00 00 02 8e 42 39 01 00 00 00 00 02 8f 11 39 01 00 00 00 00 02 90 11 39 01 00 00 00 00 02 91 11 39 01 00 00 00 00 02 9a 81 39 01 00 00 00 00 02 9b 03 39 01 00 00 00 00 02 9c 00 39 01 00 00 00 00 02 9d 00 39 01 00 00 00 00 02 9e 00 39 01 00 00 00 00 02 ff 27 39 01 00 00 00 00 02 fb 01 39 01 00 00 00 00 02 01 68 39 01 00 00 00 00 02 20 81 39 01 00 00 00 00 02 21 ea 39 01 00 00 00 00 02 25 82 39 01 00 00 00 00 02 26 1f 39 01 00 00 00 00 02 6e 00 39 01 00 00 00 00 02 6f 00 39 01 00 00 00 00 02 70 00 39 01 00 00 00 00 02 71 00 39 01 00 00 00 00 02 72 00 39 01 00 00 00 00 02 75 00 39 01 00 00 00 00 02 76 00 39 01 00 00 00 00 02 77 00 39 01 00 00 00 00 02 7d 09 39 01 00 00 00 00 02 7e 67 39 01 00 00 00 00 02 80 23 39 01 00 00 00 00 02 82 09 39 01 00 00 00 00 02 83 67 39 01 00 00 00 00 02 88 01 39 01 00 00 00 00 02 89 10 39 01 00 00 00 00 02 a5 10 39 01 00 00 00 00 02 a6 23 39 01 00 00 00 00 02 a7 01 39 01 00 00 00 00 02 b6 40 39 01 00 00 00 00 02 e3 02 39 01 00 00 00 00 02 e4 e0 39 01 00 00 00 00 02 e5 01 39 01 00 00 00 00 02 e6 70 39 01 00 00 00 00 02 e9 03 39 01 00 00 00 00 02 ea 2f 39 01 00 00 00 00 02 eb 01 39 01 00 00 00 00 02 ec 98 39 01 00 00 00 00 02 ff 2a 39 01 00 00 00 00 02 fb 01 39 01 00 00 00 00 02 00 91 39 01 00 00 00 00 02 03 20 39 01 00 00 00 00 02 07 5a 39 01 00 00 00 00 02 0a 70 39 01 00 00 00 00 02 0d 40 39 01 00 00 00 00 02 0e 02 39 01 00 00 00 00 02 11 f0 39 01 00 00 00 00 02 15 0f 39 01 00 00 00 00 02 16 65 39 01 00 00 00 00 02 19 0f 39 01 00 00 00 00 02 1a 39 39 01 00 00 00 00 02 1b 14 39 01 00 00 00 00 02 1d 36 39 01 00 00 00 00 02 1e 4f 39 01 00 00 00 00 02 1f 4f 39 01 00 00 00 00 02 20 4f 39 01 00 00 00 00 02 28 e4 39 01 00 00 00 00 02 29 17 39 01 00 00 00 00 02 2a f5 39 01 00 00 00 00 02 2d 06 39 01 00 00 00 00 02 2f 04 39 01 00 00 00 00 02 30 54 39 01 00 00 00 00 02 33 04 39 01 00 00 00 00 02 34 e6 39 01 00 00 00 00 02 35 32 39 01 00 00 00 00 02 36 02 39 01 00 00 00 00 02 37 e1 39 01 00 00 00 00 02 38 36 39 01 00 00 00 00 02 39 fe 39 01 00 00 00 00 02 3a 14 39 01 00 00 00 00 02 46 40 39 01 00 00 00 00 02 47 02 39 01 00 00 00 00 02 4a f0 39 01 00 00 00 00 02 4e 0f 39 01 00 00 00 00 02 4f 65 39 01 00 00 00 00 02 52 0f 39 01 00 00 00 00 02 53 39 39 01 00 00 00 00 02 54 14 39 01 00 00 00 00 02 56 36 39 01 00 00 00 00 02 57 7e 39 01 00 00 00 00 02 58 7e 39 01 00 00 00 00 02 59 7e 39 01 00 00 00 00 02 60 80 39 01 00 00 00 00 02 61 c9 39 01 00 00 00 00 02 62 03 39 01 00 00 00 00 02 63 fb 39 01 00 00 00 00 02 64 03 39 01 00 00 00 00 02 65 05 39 01 00 00 00 00 02 66 01 39 01 00 00 00 00 02 67 04 39 01 00 00 00 00 02 68 91 39 01 00 00 00 00 02 6a 19 39 01 00 00 00 00 02 6b cb 39 01 00 00 00 00 02 6c 20 39 01 00 00 00 00 02 6d e5 39 01 00 00 00 00 02 6e c8 39 01 00 00 00 00 02 6f 22 39 01 00 00 00 00 02 70 e3 39 01 00 00 00 00 02 71 04 39 01 00 00 00 00 02 7a 07 39 01 00 00 00 00 02 7b 40 39 01 00 00 00 00 02 7d 01 39 01 00 00 00 00 02 7f 2c 39 01 00 00 00 00 02 83 0f 39 01 00 00 00 00 02 84 65 39 01 00 00 00 00 02 87 0f 39 01 00 00 00 00 02 88 39 39 01 00 00 00 00 02 89 14 39 01 00 00 00 00 02 8b 36 39 01 00 00 00 00 02 8c 39 39 01 00 00 00 00 02 8d 39 39 01 00 00 00 00 02 8e 39 39 01 00 00 00 00 02 95 80 39 01 00 00 00 00 02 96 fd 39 01 00 00 00 00 02 97 14 39 01 00 00 00 00 02 98 b3 39 01 00 00 00 00 02 99 01 39 01 00 00 00 00 02 9a 08 39 01 00 00 00 00 02 9b 02 39 01 00 00 00 00 02 9c 4c 39 01 00 00 00 00 02 9d bc 39 01 00 00 00 00 02 9f ac 39 01 00 00 00 00 02 a0 ff 39 01 00 00 00 00 02 a2 44 39 01 00 00 00 00 02 a3 78 39 01 00 00 00 00 02 a4 f8 39 01 00 00 00 00 02 a5 4a 39 01 00 00 00 00 02 a6 72 39 01 00 00 00 00 02 a7 4c 39 01 00 00 00 00 02 ff 2c 39 01 00 00 00 00 02 fb 01 39 01 00 00 00 00 02 00 02 39 01 00 00 00 00 02 01 02 39 01 00 00 00 00 02 02 02 39 01 00 00 00 00 02 03 16 39 01 00 00 00 00 02 04 16 39 01 00 00 00 00 02 05 16 39 01 00 00 00 00 02 0d 1f 39 01 00 00 00 00 02 0e 1f 39 01 00 00 00 00 02 16 1b 39 01 00 00 00 00 02 17 4b 39 01 00 00 00 00 02 18 4b 39 01 00 00 00 00 02 19 4b 39 01 00 00 00 00 02 2a 03 39 01 00 00 00 00 02 4d 16 39 01 00 00 00 00 02 4e 02 39 01 00 00 00 00 02 4f 2f 39 01 00 00 00 00 02 53 02 39 01 00 00 00 00 02 54 02 39 01 00 00 00 00 02 55 02 39 01 00 00 00 00 02 56 0e 39 01 00 00 00 00 02 58 0e 39 01 00 00 00 00 02 59 0e 39 01 00 00 00 00 02 61 1f 39 01 00 00 00 00 02 62 1f 39 01 00 00 00 00 02 6a 14 39 01 00 00 00 00 02 6b 34 39 01 00 00 00 00 02 6c 34 39 01 00 00 00 00 02 6d 34 39 01 00 00 00 00 02 7e 03 39 01 00 00 00 00 02 9d 0e 39 01 00 00 00 00 02 9e 02 39 01 00 00 00 00 02 9f 02 39 01 00 00 00 00 02 ff 20 39 01 00 00 00 00 02 fb 01 39 01 00 00 00 00 11 b0 00 00 00 15 00 3f 00 5f 00 7e 00 97 00 af 00 c3 39 01 00 00 00 00 11 b1 00 d7 01 0a 01 32 01 6f 01 9e 01 e5 02 1d 02 1e 39 01 00 00 00 00 11 b2 02 56 02 94 02 bc 02 f1 03 13 03 41 03 4f 03 5f 39 01 00 00 00 00 0f b3 03 71 03 84 03 99 03 b0 03 ca 03 d7 00 00 39 01 00 00 00 00 11 b4 00 00 00 17 00 46 00 69 00 8c 00 a5 00 be 00 d1 39 01 00 00 00 00 11 b5 00 e4 01 18 01 40 01 7c 01 aa 01 f0 02 27 02 28 39 01 00 00 00 00 11 b6 02 5e 02 9b 02 c3 02 f6 03 18 03 45 03 54 03 63 39 01 00 00 00 00 0f b7 03 75 03 87 03 9c 03 b2 03 ca 03 d7 00 00 39 01 00 00 00 00 11 b8 00 00 00 18 00 49 00 6b 00 8e 00 a8 00 c1 00 d3 39 01 00 00 00 00 11 b9 00 e5 01 18 01 3f 01 7b 01 a8 01 ec 02 24 02 26 39 01 00 00 00 00 11 ba 02 5a 02 97 02 c0 02 f4 03 15 03 43 03 51 03 61 39 01 00 00 00 00 0f bb 03 72 03 85 03 9a 03 b1 03 ca 03 d7 00 00 39 01 00 00 00 00 02 c6 00 39 01 00 00 00 00 02 c7 00 39 01 00 00 00 00 02 c8 00 39 01 00 00 00 00 02 c9 00 39 01 00 00 00 00 02 ca 00 39 01 00 00 00 00 02 cb 00 39 01 00 00 00 00 02 cc 00 39 01 00 00 00 00 02 cd 00 39 01 00 00 00 00 02 ce 00 39 01 00 00 00 00 02 cf 00 39 01 00 00 00 00 02 d0 00 39 01 00 00 00 00 02 d1 00 39 01 00 00 00 00 02 d2 00 39 01 00 00 00 00 02 d3 00 39 01 00 00 00 00 02 d4 00 39 01 00 00 00 00 02 d5 00 39 01 00 00 00 00 02 d6 00 39 01 00 00 00 00 02 d7 00 39 01 00 00 00 00 02 d8 00 39 01 00 00 00 00 02 d9 00 39 01 00 00 00 00 02 da 00 39 01 00 00 00 00 02 db 00 39 01 00 00 00 00 02 dc 00 39 01 00 00 00 00 02 dd 00 39 01 00 00 00 00 02 de 00 39 01 00 00 00 00 02 df 00 39 01 00 00 00 00 02 e0 00 39 01 00 00 00 00 02 e1 00 39 01 00 00 00 00 02 e2 00 39 01 00 00 00 00 02 e3 00 39 01 00 00 00 00 02 e4 00 39 01 00 00 00 00 02 e5 00 39 01 00 00 00 00 02 e6 00 39 01 00 00 00 00 02 e7 00 39 01 00 00 00 00 02 e8 00 39 01 00 00 00 00 02 e9 00 39 01 00 00 00 00 02 ff 21 39 01 00 00 00 00 02 fb 01 39 01 00 00 00 00 11 b0 00 00 00 15 00 3f 00 5f 00 7e 00 97 00 af 00 c3 39 01 00 00 00 00 11 b1 00 d7 01 0a 01 32 01 6f 01 9e 01 e5 02 1d 02 1e 39 01 00 00 00 00 11 b2 02 56 02 94 02 bc 02 f1 03 13 03 41 03 4f 03 5f 39 01 00 00 00 00 0f b3 03 71 03 84 03 99 03 b0 03 ca 03 d7 00 00 39 01 00 00 00 00 11 b4 00 00 00 17 00 46 00 69 00 8c 00 a5 00 be 00 d1 39 01 00 00 00 00 11 b5 00 e4 01 18 01 40 01 7c 01 aa 01 f0 02 27 02 28 39 01 00 00 00 00 11 b6 02 5e 02 9b 02 c3 02 f6 03 18 03 45 03 54 03 63 39 01 00 00 00 00 0f b7 03 75 03 87 03 9c 03 b2 03 ca 03 d7 00 00 39 01 00 00 00 00 11 b8 00 00 00 18 00 49 00 6b 00 8e 00 a8 00 c1 00 d3 39 01 00 00 00 00 11 b9 00 e5 01 18 01 3f 01 7b 01 a8 01 ec 02 24 02 26 39 01 00 00 00 00 11 ba 02 5a 02 97 02 c0 02 f4 03 15 03 43 03 51 03 61 39 01 00 00 00 00 0f bb 03 72 03 85 03 9a 03 b1 03 ca 03 d7 00 00 39 01 00 00 00 00 02 ff e0 39 01 00 00 00 00 02 fb 01 39 01 00 00 00 00 02 35 82 39 01 00 00 00 00 02 85 32 39 01 00 00 00 00 02 ff f0 39 01 00 00 00 00 02 fb 01 39 01 00 00 00 00 02 1c 01 39 01 00 00 00 00 02 33 01 39 01 00 00 00 00 02 5a 00 39 01 00 00 00 00 02 ff d0 39 01 00 00 00 00 02 fb 01 39 01 00 00 00 00 02 53 22 39 01 00 00 00 00 02 54 02 39 01 00 00 00 00 02 ff c0 39 01 00 00 00 00 02 fb 01 39 01 00 00 00 00 02 9c 11 39 01 00 00 00 00 02 9d 11 39 01 00 00 00 00 02 ff 2b 39 01 00 00 00 00 02 fb 01 39 01 00 00 00 00 02 b7 0a 39 01 00 00 00 00 02 b8 1c 39 01 00 00 00 00 02 c0 01 39 01 00 00 00 00 02 ff 10 39 01 00 00 00 00 02 35 01 39 01 00 00 00 00 02 51 ff 39 01 00 00 00 00 02 53 0c 39 01 00 00 00 00 02 55 00 05 01 00 00 78 00 01 11 05 01 00 00 28 00 01 29];
				qcom,mdss-dsi-on-command-state = "dsi_lp_mode";
				qcom,mdss-dsi-off-command = <0x5010000 0x10000128 0x5010000 0x32000110>;
				qcom,mdss-dsi-off-command-state = "dsi_lp_mode";
				qcom,compression-mode = "dsc";
				qcom,mdss-dsc-slice-height = <0x8>;
				qcom,mdss-dsc-slice-width = <0x21c>;
				qcom,mdss-dsc-slice-per-pkt = <0x1>;
				qcom,mdss-dsc-bit-per-component = <0x8>;
				qcom,mdss-dsc-bit-per-pixel = <0x8>;
				qcom,mdss-dsc-block-prediction-enable;
				qcom,mdss-dsi-panel-phy-timings = [00 18 06 06 21 20 06 06 07 02 04 00 16 16];
				qcom,display-topology = <0x1 0x1 0x1>;
				qcom,default-topology-index = <0x0>;
			};
		};
	};

	dsi_nt36672e_fhd_plus_60_video: qcom,mdss_dsi_nt36672e_fhd_plus_60_video {
		qcom,mdss-dsi-panel-name = "nt36672e 60 Hz fhd plus video mode panel without DSC";
		qcom,mdss-dsi-panel-type = "dsi_video_mode";
		qcom,dsi-ctrl-num = <0x0>;
		qcom,dsi-phy-num = <0x0>;
		qcom,mdss-dsi-virtual-channel-id = <0x0>;
		qcom,mdss-dsi-stream = <0x0>;
		qcom,mdss-dsi-bpp = <0x18>;
		qcom,mdss-dsi-border-color = <0x0>;
		qcom,mdss-dsi-traffic-mode = "burst_mode";
		qcom,mdss-dsi-bllp-power-mode;
		qcom,mdss-dsi-bllp-eof-power-mode;
		qcom,mdss-dsi-lane-0-state;
		qcom,mdss-dsi-lane-1-state;
		qcom,mdss-dsi-lane-2-state;
		qcom,mdss-dsi-lane-3-state;
		qcom,mdss-dsi-dma-trigger = "trigger_sw";
		qcom,mdss-dsi-mdp-trigger = "none";
		qcom,mdss-dsi-reset-sequence = <0x1 0xa 0x0 0xa 0x1 0xa>;
		qcom,mdss-dsi-tx-eot-append;
		qcom,adjust-timer-wakeup-ms = <0x1>;
		qcom,mdss-dsi-panel-hdr-enabled;
		qcom,mdss-dsi-panel-hdr-color-primaries = <0x9858 0x3e80 0x83d6 0x9b78 0x33c2 0x8692 0x1d4c 0xbb8>;
		qcom,mdss-dsi-panel-peak-brightness = <0x626b50>;
		qcom,mdss-dsi-panel-blackness-level = <0x1361>;
		qcom,dsi-select-clocks = "mux_byte_clk0", "mux_pixel_clk0";
		qcom,esd-check-enabled;
		qcom,mdss-dsi-panel-status-check-mode = "reg_read";
		qcom,mdss-dsi-panel-status-command = <0x6010001 0x10a>;
		qcom,mdss-dsi-panel-status-command-state = "dsi_lp_mode";
		qcom,mdss-dsi-panel-status-value = <0x9c>;
		qcom,mdss-dsi-panel-status-read-length = <0x1>;
		qcom,panel-supply-entries = <&dsi_panel_pwr_supply_labibb>;
		qcom,mdss-dsi-bl-pmic-control-type = "bl_ctrl_wled";
		qcom,mdss-dsi-bl-min-level = <0x1>;
		qcom,mdss-dsi-bl-max-level = <0xfff>;
		qcom,platform-reset-gpio = <&tlmm 0x2c 0x0>;

		qcom,mdss-dsi-display-timings {

			timing@0 {
				qcom,mdss-dsi-panel-width = <0x438>;
				qcom,mdss-dsi-panel-height = <0x968>;
				qcom,mdss-dsi-h-front-porch = <0x4c>;
				qcom,mdss-dsi-h-back-porch = <0x38>;
				qcom,mdss-dsi-h-pulse-width = <0xc>;
				qcom,mdss-dsi-h-sync-skew = <0x0>;
				qcom,mdss-dsi-v-back-porch = <0xa>;
				qcom,mdss-dsi-v-front-porch = <0x2e>;
				qcom,mdss-dsi-v-pulse-width = <0xa>;
				qcom,mdss-dsi-panel-framerate = <0x3c>;
				qcom,mdss-dsi-on-command = [39 01 00 00 00 00 02 ff 10 39 01 00 00 00 00 02 fb 01 39 01 00 00 00 00 02 b0 00 39 01 00 00 00 00 02 c0 00 39 01 00 00 00 00 11 c1 89 28 00 08 00 aa 02 0e 00 2b 00 07 0d b7 0c b7 39 01 00 00 00 00 03 c2 1b a0 39 01 00 00 00 00 02 ff 20 39 01 00 00 00 00 02 fb 01 39 01 00 00 00 00 02 01 66 39 01 00 00 00 00 02 06 40 39 01 00 00 00 00 02 07 38 39 01 00 00 00 00 02 2f 83 39 01 00 00 00 00 02 69 91 39 01 00 00 00 00 02 95 d1 39 01 00 00 00 00 02 96 d1 39 01 00 00 00 00 02 f2 64 39 01 00 00 00 00 02 f3 54 39 01 00 00 00 00 02 f4 64 39 01 00 00 00 00 02 f5 54 39 01 00 00 00 00 02 f6 64 39 01 00 00 00 00 02 f7 54 39 01 00 00 00 00 02 f8 64 39 01 00 00 00 00 02 f9 54 39 01 00 00 00 00 02 ff 24 39 01 00 00 00 00 02 fb 01 39 01 00 00 00 00 02 01 0f 39 01 00 00 00 00 02 03 0c 39 01 00 00 00 00 02 05 1d 39 01 00 00 00 00 02 08 2f 39 01 00 00 00 00 02 09 2e 39 01 00 00 00 00 02 0a 2d 39 01 00 00 00 00 02 0b 2c 39 01 00 00 00 00 02 11 17 39 01 00 00 00 00 02 12 13 39 01 00 00 00 00 02 13 15 39 01 00 00 00 00 02 15 14 39 01 00 00 00 00 02 16 16 39 01 00 00 00 00 02 17 18 39 01 00 00 00 00 02 1b 01 39 01 00 00 00 00 02 1d 1d 39 01 00 00 00 00 02 20 2f 39 01 00 00 00 00 02 21 2e 39 01 00 00 00 00 02 22 2d 39 01 00 00 00 00 02 23 2c 39 01 00 00 00 00 02 29 17 39 01 00 00 00 00 02 2a 13 39 01 00 00 00 00 02 2b 15 39 01 00 00 00 00 02 2f 14 39 01 00 00 00 00 02 30 16 39 01 00 00 00 00 02 31 18 39 01 00 00 00 00 02 32 04 39 01 00 00 00 00 02 34 10 39 01 00 00 00 00 02 35 1f 39 01 00 00 00 00 02 36 1f 39 01 00 00 00 00 02 4d 14 39 01 00 00 00 00 02 4e 36 39 01 00 00 00 00 02 4f 36 39 01 00 00 00 00 02 53 36 39 01 00 00 00 00 02 71 30 39 01 00 00 00 00 02 79 11 39 01 00 00 00 00 02 7a 82 39 01 00 00 00 00 02 7b 8f 39 01 00 00 00 00 02 7d 04 39 01 00 00 00 00 02 80 04 39 01 00 00 00 00 02 81 04 39 01 00 00 00 00 02 82 13 39 01 00 00 00 00 02 84 31 39 01 00 00 00 00 02 85 00 39 01 00 00 00 00 02 86 00 39 01 00 00 00 00 02 87 00 39 01 00 00 00 00 02 90 13 39 01 00 00 00 00 02 92 31 39 01 00 00 00 00 02 93 00 39 01 00 00 00 00 02 94 00 39 01 00 00 00 00 02 95 00 39 01 00 00 00 00 02 9c f4 39 01 00 00 00 00 02 9d 01 39 01 00 00 00 00 02 a0 0f 39 01 00 00 00 00 02 a2 0f 39 01 00 00 00 00 02 a3 02 39 01 00 00 00 00 02 a4 04 39 01 00 00 00 00 02 a5 04 39 01 00 00 00 00 02 c6 c0 39 01 00 00 00 00 02 c9 00 39 01 00 00 00 00 02 d9 80 39 01 00 00 00 00 02 e9 02 39 01 00 00 00 00 02 ff 25 39 01 00 00 00 00 02 fb 01 39 01 00 00 00 00 02 18 22 39 01 00 00 00 00 02 19 e4 39 01 00 00 00 00 02 21 40 39 01 00 00 00 00 02 66 d8 39 01 00 00 00 00 02 68 50 39 01 00 00 00 00 02 69 10 39 01 00 00 00 00 02 6b 00 39 01 00 00 00 00 02 6d 0d 39 01 00 00 00 00 02 6e 48 39 01 00 00 00 00 02 72 41 39 01 00 00 00 00 02 73 4a 39 01 00 00 00 00 02 74 d0 39 01 00 00 00 00 02 77 62 39 01 00 00 00 00 02 79 7e 39 01 00 00 00 00 02 7d 03 39 01 00 00 00 00 02 7e 15 39 01 00 00 00 00 02 7f 00 39 01 00 00 00 00 02 84 4d 39 01 00 00 00 00 02 cf 80 39 01 00 00 00 00 02 d6 80 39 01 00 00 00 00 02 d7 80 39 01 00 00 00 00 02 ef 20 39 01 00 00 00 00 02 f0 84 39 01 00 00 00 00 02 ff 26 39 01 00 00 00 00 02 fb 01 39 01 00 00 00 00 02 81 0f 39 01 00 00 00 00 02 83 01 39 01 00 00 00 00 02 84 03 39 01 00 00 00 00 02 85 01 39 01 00 00 00 00 02 86 03 39 01 00 00 00 00 02 87 01 39 01 00 00 00 00 02 88 05 39 01 00 00 00 00 02 8a 1a 39 01 00 00 00 00 02 8b 11 39 01 00 00 00 00 02 8c 24 39 01 00 00 00 00 02 8e 42 39 01 00 00 00 00 02 8f 11 39 01 00 00 00 00 02 90 11 39 01 00 00 00 00 02 91 11 39 01 00 00 00 00 02 9a 80 39 01 00 00 00 00 02 9b 04 39 01 00 00 00 00 02 9c 00 39 01 00 00 00 00 02 9d 00 39 01 00 00 00 00 02 9e 00 39 01 00 00 00 00 02 ff 27 39 01 00 00 00 00 02 fb 01 39 01 00 00 00 00 02 01 68 39 01 00 00 00 00 02 20 81 39 01 00 00 00 00 02 21 6a 39 01 00 00 00 00 02 25 81 39 01 00 00 00 00 02 26 94 39 01 00 00 00 00 02 6e 00 39 01 00 00 00 00 02 6f 00 39 01 00 00 00 00 02 70 00 39 01 00 00 00 00 02 71 00 39 01 00 00 00 00 02 72 00 39 01 00 00 00 00 02 75 00 39 01 00 00 00 00 02 76 00 39 01 00 00 00 00 02 77 00 39 01 00 00 00 00 02 7d 09 39 01 00 00 00 00 02 7e 67 39 01 00 00 00 00 02 80 23 39 01 00 00 00 00 02 82 09 39 01 00 00 00 00 02 83 67 39 01 00 00 00 00 02 88 01 39 01 00 00 00 00 02 89 10 39 01 00 00 00 00 02 a5 10 39 01 00 00 00 00 02 a6 23 39 01 00 00 00 00 02 a7 01 39 01 00 00 00 00 02 b6 40 39 01 00 00 00 00 02 e5 02 39 01 00 00 00 00 02 e6 d3 39 01 00 00 00 00 02 eb 03 39 01 00 00 00 00 02 ec 28 39 01 00 00 00 00 02 ff 2a 39 01 00 00 00 00 02 fb 01 39 01 00 00 00 00 02 00 91 39 01 00 00 00 00 02 03 20 39 01 00 00 00 00 02 07 50 39 01 00 00 00 00 02 0a 70 39 01 00 00 00 00 02 0c 04 39 01 00 00 00 00 02 0d 40 39 01 00 00 00 00 02 0f 01 39 01 00 00 00 00 02 11 e0 39 01 00 00 00 00 02 15 0f 39 01 00 00 00 00 02 16 a4 39 01 00 00 00 00 02 19 0f 39 01 00 00 00 00 02 1a 78 39 01 00 00 00 00 02 1b 23 39 01 00 00 00 00 02 1d 36 39 01 00 00 00 00 02 1e 3e 39 01 00 00 00 00 02 1f 3e 39 01 00 00 00 00 02 20 3e 39 01 00 00 00 00 02 28 fd 39 01 00 00 00 00 02 29 12 39 01 00 00 00 00 02 2a e1 39 01 00 00 00 00 02 2d 0a 39 01 00 00 00 00 02 30 49 39 01 00 00 00 00 02 33 96 39 01 00 00 00 00 02 34 ff 39 01 00 00 00 00 02 35 40 39 01 00 00 00 00 02 36 de 39 01 00 00 00 00 02 37 f9 39 01 00 00 00 00 02 38 45 39 01 00 00 00 00 02 39 d9 39 01 00 00 00 00 02 3a 49 39 01 00 00 00 00 02 4a f0 39 01 00 00 00 00 02 7a 09 39 01 00 00 00 00 02 7b 40 39 01 00 00 00 00 02 7f f0 39 01 00 00 00 00 02 83 0f 39 01 00 00 00 00 02 84 a4 39 01 00 00 00 00 02 87 0f 39 01 00 00 00 00 02 88 78 39 01 00 00 00 00 02 89 23 39 01 00 00 00 00 02 8b 36 39 01 00 00 00 00 02 8c 7d 39 01 00 00 00 00 02 8d 7d 39 01 00 00 00 00 02 8e 7d 39 01 00 00 00 00 02 ff 20 39 01 00 00 00 00 02 fb 01 39 01 00 00 00 00 11 b0 00 00 00 17 00 49 00 6a 00 89 00 9f 00 b6 00 c8 39 01 00 00 00 00 11 b1 00 d9 01 10 01 3a 01 7a 01 a9 01 f2 02 2d 02 2e 39 01 00 00 00 00 11 b2 02 64 02 a3 02 ca 03 00 03 1e 03 4a 03 59 03 6a 39 01 00 00 00 00 0f b3 03 7d 03 93 03 ab 03 c8 03 ec 03 fe 00 00 39 01 00 00 00 00 11 b4 00 00 00 1b 00 51 00 71 00 90 00 a7 00 bf 00 d1 39 01 00 00 00 00 11 b5 00 e2 01 1a 01 43 01 83 01 b2 01 fa 02 34 02 36 39 01 00 00 00 00 11 b6 02 6b 02 a8 02 d0 03 03 03 21 03 4d 03 5b 03 6b 39 01 00 00 00 00 0f b7 03 7e 03 94 03 ac 03 c8 03 ec 03 fe 00 00 39 01 00 00 00 00 11 b8 00 00 00 1b 00 51 00 72 00 92 00 a8 00 bf 00 d1 39 01 00 00 00 00 11 b9 00 e2 01 18 01 42 01 81 01 af 01 f5 02 2f 02 31 39 01 00 00 00 00 11 ba 02 68 02 a6 02 cd 03 01 03 1f 03 4a 03 59 03 6a 39 01 00 00 00 00 0f bb 03 7d 03 93 03 ab 03 c8 03 ec 03 fe 00 00 39 01 00 00 00 00 02 ff 21 39 01 00 00 00 00 02 fb 01 39 01 00 00 00 00 11 b0 00 00 00 17 00 49 00 6a 00 89 00 9f 00 b6 00 c8 39 01 00 00 00 00 11 b1 00 d9 01 10 01 3a 01 7a 01 a9 01 f2 02 2d 02 2e 39 01 00 00 00 00 11 b2 02 64 02 a3 02 ca 03 00 03 1e 03 4a 03 59 03 6a 39 01 00 00 00 00 0f b3 03 7d 03 93 03 ab 03 c8 03 ec 03 fe 00 00 39 01 00 00 00 00 11 b4 00 00 00 1b 00 51 00 71 00 90 00 a7 00 bf 00 d1 39 01 00 00 00 00 11 b5 00 e2 01 1a 01 43 01 83 01 b2 01 fa 02 34 02 36 39 01 00 00 00 00 11 b6 02 6b 02 a8 02 d0 03 03 03 21 03 4d 03 5b 03 6b 39 01 00 00 00 00 0f b7 03 7e 03 94 03 ac 03 c8 03 ec 03 fe 00 00 39 01 00 00 00 00 11 b8 00 00 00 1b 00 51 00 72 00 92 00 a8 00 bf 00 d1 39 01 00 00 00 00 11 b9 00 e2 01 18 01 42 01 81 01 af 01 f5 02 2f 02 31 39 01 00 00 00 00 11 ba 02 68 02 a6 02 cd 03 01 03 1f 03 4a 03 59 03 6a 39 01 00 00 00 00 0f bb 03 7d 03 93 03 ab 03 c8 03 ec 03 fe 00 00 39 01 00 00 00 00 02 ff 2c 39 01 00 00 00 00 02 fb 01 39 01 00 00 00 00 02 61 1f 39 01 00 00 00 00 02 62 1f 39 01 00 00 00 00 02 7e 03 39 01 00 00 00 00 02 6a 14 39 01 00 00 00 00 02 6b 36 39 01 00 00 00 00 02 6c 36 39 01 00 00 00 00 02 6d 36 39 01 00 00 00 00 02 53 04 39 01 00 00 00 00 02 54 04 39 01 00 00 00 00 02 55 04 39 01 00 00 00 00 02 56 0f 39 01 00 00 00 00 02 58 0f 39 01 00 00 00 00 02 59 0f 39 01 00 00 00 00 02 ff f0 39 01 00 00 00 00 02 fb 01 39 01 00 00 00 00 02 5a 00 15 01 00 00 00 00 02 ff 10 15 01 00 00 00 00 02 fb 01 15 01 00 00 00 00 02 51 ff 15 01 00 00 00 00 02 53 24 15 01 00 00 00 00 02 55 01 05 01 00 00 78 00 01 11 05 01 00 00 64 00 01 29];
				qcom,mdss-dsi-on-command-state = "dsi_lp_mode";
				qcom,mdss-dsi-off-command = <0x5010000 0x10000128 0x5010000 0x32000110>;
				qcom,mdss-dsi-panel-phy-timings = [00 24 09 0a 26 25 09 0a 09 02 04 00 1f 19];
				qcom,display-topology = <0x1 0x0 0x1>;
				qcom,default-topology-index = <0x0>;
			};
		};
	};

	dsi_nt36672e_fhd_plus_144hz_video_cphy: qcom,mdss_dsi_nt36672e_fhd_plus_cphy_144hz_video {
		qcom,mdss-dsi-panel-name = "nt36672e 144Hz fhd plus video mode cphy panel with DSC";
		qcom,mdss-dsi-panel-type = "dsi_video_mode";
		qcom,dsi-ctrl-num = <0x0>;
		qcom,dsi-phy-num = <0x0>;
		qcom,mdss-dsi-virtual-channel-id = <0x0>;
		qcom,mdss-dsi-stream = <0x0>;
		qcom,mdss-dsi-bpp = <0x18>;
		qcom,mdss-dsi-border-color = <0x0>;
		qcom,mdss-dsi-traffic-mode = "burst_mode";
		qcom,mdss-dsi-bllp-power-mode;
		qcom,mdss-dsi-bllp-eof-power-mode;
		qcom,mdss-dsi-lane-0-state;
		qcom,mdss-dsi-lane-1-state;
		qcom,mdss-dsi-lane-2-state;
		qcom,mdss-dsi-dma-trigger = "trigger_sw";
		qcom,mdss-dsi-mdp-trigger = "none";
		qcom,mdss-dsi-reset-sequence = <0x1 0xa 0x0 0xa 0x1 0xa>;
		qcom,mdss-dsi-tx-eot-append;
		qcom,adjust-timer-wakeup-ms = <0x1>;
		qcom,panel-cphy-mode;
		qcom,mdss-dsi-panel-hdr-enabled;
		qcom,mdss-dsi-panel-hdr-color-primaries = <0x9858 0x3e80 0x83d6 0x9b78 0x33c2 0x8692 0x1d4c 0xbb8>;
		qcom,mdss-dsi-panel-peak-brightness = <0x626b50>;
		qcom,mdss-dsi-panel-blackness-level = <0x1361>;
		qcom,dsi-select-clocks = "mux_byte_clk0", "mux_pixel_clk0", "cphy_byte_clk0", "cphy_pixel_clk0";
		qcom,panel-supply-entries = <&dsi_panel_pwr_supply_labibb>;
		qcom,mdss-dsi-bl-pmic-control-type = "bl_ctrl_wled";
		qcom,mdss-dsi-bl-min-level = <0x1>;
		qcom,mdss-dsi-bl-max-level = <0xfff>;
		qcom,platform-reset-gpio = <&tlmm 0x2c 0x0>;

		qcom,mdss-dsi-display-timings {

			timing@0 {
				qcom,mdss-dsi-panel-width = <0x438>;
				qcom,mdss-dsi-panel-height = <0x960>;
				qcom,mdss-dsi-h-front-porch = <0x4c>;
				qcom,mdss-dsi-h-back-porch = <0x50>;
				qcom,mdss-dsi-h-pulse-width = <0xc>;
				qcom,mdss-dsi-h-sync-skew = <0x0>;
				qcom,mdss-dsi-v-back-porch = <0xa>;
				qcom,mdss-dsi-v-front-porch = <0x36>;
				qcom,mdss-dsi-v-pulse-width = <0xa>;
				qcom,mdss-dsi-panel-framerate = <0x90>;
				qcom,mdss-dsi-on-command = <0x39010000 0x2ff 0x10390100 0x2 0xfb013901 0x0 0x2b00039 0x1000000 0x2c003 0x39010000 0x11c1 0x89280008 0xaa020e 0x2b0007 0xdb70cb7 0x39010000 0x3c2 0x1ba03901 0x0 0x2e90139 0x1000000 0x2ff20 0x39010000 0x2fb 0x1390100 0x2 0x1663901 0x0 0x2064039 0x1000000 0x20738 0x39010000 0x218 0x77390100 0x2 0x69913901 0x0 0x295d139 0x1000000 0x296d1 0x39010000 0x2f2 0x65390100 0x2 0xf3743901 0x0 0x2f46539 0x1000000 0x2f574 0x39010000 0x2f6 0x65390100 0x2 0xf7743901 0x0 0x2f86539 0x1000000 0x2f974 0x39010000 0x289 0x15390100 0x2 0x8a153901 0x0 0x28d1539 0x1000000 0x28e15 0x39010000 0x28f 0x15390100 0x2 0x91153901 0x0 0x2ff2439 0x1000000 0x2fb01 0x39010000 0x201 0xf390100 0x2 0x30c3901 0x0 0x2051d39 0x1000000 0x2082f 0x39010000 0x209 0x2e390100 0x2 0xa2d3901 0x0 0x20b2c39 0x1000000 0x21117 0x39010000 0x212 0x13390100 0x2 0x13153901 0x0 0x2151439 0x1000000 0x21616 0x39010000 0x217 0x18390100 0x2 0x1b013901 0x0 0x21d1d39 0x1000000 0x2202f 0x39010000 0x221 0x2e390100 0x2 0x222d3901 0x0 0x2232c39 0x1000000 0x22917 0x39010000 0x22a 0x13390100 0x2 0x2b153901 0x0 0x22f1439 0x1000000 0x23016 0x39010000 0x231 0x18390100 0x2 0x32043901 0x0 0x2341039 0x1000000 0x2351f 0x39010000 0x236 0x1f390100 0x2 0x4d1b3901 0x0 0x24e4b39 0x1000000 0x24f4b 0x39010000 0x253 0x4b390100 0x2 0x71303901 0x0 0x2791139 0x1000000 0x27a82 0x39010000 0x27b 0x96390100 0x2 0x7d043901 0x0 0x2800439 0x1000000 0x28104 0x39010000 0x282 0x13390100 0x2 0x84313901 0x0 0x2850039 0x1000000 0x28600 0x39010000 0x287 0x390100 0x2 0x90133901 0x0 0x2923139 0x1000000 0x29300 0x39010000 0x294 0x390100 0x2 0x95003901 0x0 0x29cf439 0x1000000 0x29d01 0x39010000 0x2a0 0x16390100 0x2 0xa2163901 0x0 0x2a30239 0x1000000 0x2a404 0x39010000 0x2a5 0x4390100 0x2 0xc6c03901 0x0 0x2c90039 0x1000000 0x2d980 0x39010000 0x2e9 0x2390100 0x2 0xff253901 0x0 0x2fb0139 0x1000000 0x21822 0x39010000 0x219 0xe4390100 0x2 0x21403901 0x0 0x266d839 0x1000000 0x26850 0x39010000 0x269 0x10390100 0x2 0x6b003901 0x0 0x26d0d39 0x1000000 0x26e48 0x39010000 0x272 0x41390100 0x2 0x734a3901 0x0 0x274d039 0x1000000 0x27762 0x39010000 0x279 0x81390100 0x2 0x7d403901 0x0 0x27e1d39 0x1000000 0x27f00 0x39010000 0x280 0x4390100 0x2 0x840d3901 0x0 0x2cf8039 0x1000000 0x2d680 0x39010000 0x2d7 0x80390100 0x2 0xef203901 0x0 0x2f08439 0x1000000 0x2ff26 0x39010000 0x2fb 0x1390100 0x2 0x15043901 0x0 0x2811639 0x1000000 0x28303 0x39010000 0x284 0x3390100 0x2 0x85013901 0x0 0x2860339 0x1000000 0x28701 0x39010000 0x28a 0x1a390100 0x2 0x8b113901 0x0 0x28c2439 0x1000000 0x28e42 0x39010000 0x28f 0x11390100 0x2 0x90113901 0x0 0x2911139 0x1000000 0x29a81 0x39010000 0x29b 0x3390100 0x2 0x9c003901 0x0 0x29d0039 0x1000000 0x29e00 0x39010000 0x2ff 0x27390100 0x2 0xfb013901 0x0 0x2016039 0x1000000 0x22081 0x39010000 0x221 0xea390100 0x2 0x25823901 0x0 0x2263f39 0x1000000 0x26e00 0x39010000 0x26f 0x390100 0x2 0x70003901 0x0 0x2710039 0x1000000 0x27200 0x39010000 0x275 0x390100 0x2 0x76003901 0x0 0x2770039 0x1000000 0x27d09 0x39010000 0x27e 0x5f390100 0x2 0x80233901 0x0 0x2820939 0x1000000 0x2835f 0x39010000 0x288 0x1390100 0x2 0x89103901 0x0 0x2a51039 0x1000000 0x2a623 0x39010000 0x2a7 0x1390100 0x2 0xb6403901 0x0 0x2e30239 0x1000000 0x2e4e0 0x39010000 0x2e5 0x1390100 0x2 0xe6333901 0x0 0x2e90339 0x1000000 0x2ea5e 0x39010000 0x2eb 0x1390100 0x2 0xec673901 0x0 0x2ff2a39 0x1000000 0x2fb01 0x39010000 0x200 0x91390100 0x2 0x3203901 0x0 0x2047339 0x1000000 0x20764 0x39010000 0x20a 0x60390100 0x2 0xc063901 0x0 0x20d4039 0x1000000 0x20e02 0x39010000 0x20f 0x1390100 0x2 0x11583901 0x0 0x2150e39 0x1000000 0x21679 0x39010000 0x219 0xd390100 0x2 0x1af23901 0x0 0x21b1439 0x1000000 0x21d36 0x39010000 0x21e 0x55390100 0x2 0x1f553901 0x0 0x2205539 0x1000000 0x2280a 0x39010000 0x229 0xb390100 0x2 0x2a4b3901 0x0 0x22b0539 0x1000000 0x22d08 0x39010000 0x22f 0x1390100 0x2 0x30473901 0x0 0x2312339 0x1000000 0x23325 0x39010000 0x234 0xff390100 0x2 0x352c3901 0x0 0x2367539 0x1000000 0x237fb 0x39010000 0x238 0x2e390100 0x2 0x39733901 0x0 0x23a4739 0x1000000 0x24640 0x39010000 0x247 0x2390100 0x2 0x4af03901 0x0 0x24e0e39 0x1000000 0x24f8b 0x39010000 0x252 0xe390100 0x2 0x53043901 0x0 0x2541439 0x1000000 0x25636 0x39010000 0x257 0x80390100 0x2 0x58803901 0x0 0x2598039 0x1000000 0x26080 0x39010000 0x261 0xa390100 0x2 0x62033901 0x0 0x263ed39 0x1000000 0x26505 0x39010000 0x266 0x1390100 0x2 0x67043901 0x0 0x2684d39 0x1000000 0x26a0a 0x39010000 0x26b 0xc9390100 0x2 0x6c1f3901 0x0 0x26de339 0x1000000 0x26ec6 0x39010000 0x26f 0x20390100 0x2 0x70e23901 0x0 0x2710439 0x1000000 0x27a04 0x39010000 0x27b 0x40390100 0x2 0x7c013901 0x0 0x27d0139 0x1000000 0x27fe0 0x39010000 0x283 0xf390100 0x2 0x84c53901 0x0 0x2870f39 0x1000000 0x28842 0x39010000 0x289 0x14390100 0x2 0x8b363901 0x0 0x28c3339 0x1000000 0x28d33 0x39010000 0x28e 0x33390100 0x2 0x95803901 0x0 0x296fd39 0x1000000 0x29719 0x39010000 0x298 0x4a390100 0x2 0x99073901 0x0 0x29a0b39 0x1000000 0x29b03 0x39010000 0x29c 0x8b390100 0x2 0x9dff3901 0x0 0x29f8b39 0x1000000 0x2a0ff 0x39010000 0x2a2 0x4e390100 0x2 0xa3013901 0x0 0x2a4f839 0x1000000 0x2a552 0x39010000 0x2a6 0xfd390100 0x2 0xa74b3901 0x0 0x2ff2c39 0x1000000 0x2fb01 0x39010000 0x200 0x2390100 0x2 0x1023901 0x0 0x2020239 0x1000000 0x20316 0x39010000 0x204 0x16390100 0x2 0x5163901 0x0 0x20d1f39 0x1000000 0x20e1f 0x39010000 0x216 0x1b390100 0x2 0x174b3901 0x0 0x2184b39 0x1000000 0x2194b 0x39010000 0x22a 0x3390100 0x2 0x4d163901 0x0 0x24e0339 0x1000000 0x25302 0x39010000 0x254 0x2390100 0x2 0x55023901 0x0 0x2560b39 0x1000000 0x2580b 0x39010000 0x259 0xb390100 0x2 0x61193901 0x0 0x2621939 0x1000000 0x26a10 0x39010000 0x26b 0x2a390100 0x2 0x6c2a3901 0x0 0x26d2a39 0x1000000 0x27e03 0x39010000 0x29d 0xb390100 0x2 0x9e043901 0x0 0x2ff2039 0x1000000 0x2fb01 0x39010000 0x11b0 0xe200e9 0xf60101 0x10c0115 0x1200128 0x39010000 0x11b1 0x1330151 0x16e019a 0x1c001fd 0x2340235 0x39010000 0x11b2 0x26b02a9 0x2d10304 0x3250351 0x35f036d 0x39010000 0xfb3 0x37d0390 0x3a703bb 0x3d403d8 0x3901 0x0 0x11b400aa 0xb300c4 0xd400e2 0xf000fc 0x1083901 0x0 0x11b50112 0x1390158 0x18c01b5 0x1f70230 0x2313901 0x0 0x11b60268 0x2a602ce 0x3010323 0x34e035c 0x36a3901 0x0 0xfb7037b 0x38e03a5 0x3bb03d4 0x3d80000 0x39010000 0x11b8 0x20 0x470065 0x850099 0xad00c0 0x39010000 0x11b9 0xd20106 0x1300170 0x19f01e8 0x2250226 0x39010000 0x11ba 0x25f029f 0x2c702fd 0x3200352 0x3630367 0x39010000 0xfbb 0x378038b 0x3a303b9 0x3d403d8 0x3901 0x0 0x2ff2139 0x1000000 0x2fb01 0x39010000 0x11b0 0xe200e9 0xf60101 0x10c0115 0x1200128 0x39010000 0x11b1 0x1330151 0x16e019a 0x1c001fd 0x2340235 0x39010000 0x11b2 0x26b02a9 0x2d10304 0x3250351 0x35f036d 0x39010000 0xfb3 0x37d0390 0x3a703bb 0x3d403d8 0x3901 0x0 0x11b400aa 0xb300c4 0xd400e2 0xf000fc 0x1083901 0x0 0x11b50112 0x1390158 0x18c01b5 0x1f70230 0x2313901 0x0 0x11b60268 0x2a602ce 0x3010323 0x34e035c 0x36a3901 0x0 0xfb7037b 0x38e03a5 0x3bb03d4 0x3d80000 0x39010000 0x11b8 0x20 0x470065 0x850099 0xad00c0 0x39010000 0x11b9 0xd20106 0x1300170 0x19f01e8 0x2250226 0x39010000 0x11ba 0x25f029f 0x2c702fd 0x3200352 0x3630367 0x39010000 0xfbb 0x378038b 0x3a303b9 0x3d403d8 0x3901 0x0 0x2ffe039 0x1000000 0x2fb01 0x39010000 0x235 0x82390100 0x2 0xfff03901 0x0 0x2fb0139 0x1000000 0x25a00 0x39010000 0x2d2 0x52390100 0x2 0x9f123901 0x0 0x2ffd039 0x1000000 0x2fb01 0x39010000 0x253 0x22390100 0x2 0x54023901 0x0 0x2ffc039 0x1000000 0x2fb01 0x39010000 0x29c 0x11390100 0x2 0x9d113901 0x0 0x2ff1039 0x1000000 0x2fb01 0x39010000 0x235 0x1390100 0x2 0x51ff3901 0x0 0x2530c39 0x1000000 0x25500 0x5010000 0x78000111 0x5010000 0x32000129>;
				qcom,mdss-dsi-on-command-state = "dsi_lp_mode";
				qcom,mdss-dsi-off-command = <0x5010000 0x10000128 0x5010000 0x32000110>;
				qcom,mdss-dsi-off-command-state = "dsi_lp_mode";
				qcom,compression-mode = "dsc";
				qcom,mdss-dsc-slice-height = <0x8>;
				qcom,mdss-dsc-slice-width = <0x21c>;
				qcom,mdss-dsc-slice-per-pkt = <0x1>;
				qcom,mdss-dsc-bit-per-component = <0x8>;
				qcom,mdss-dsc-bit-per-pixel = <0x8>;
				qcom,mdss-dsc-block-prediction-enable;
				qcom,mdss-dsi-panel-phy-timings = [00 00 00 00 22 1f 06 19 07 02 04 00 00 00];
				qcom,display-topology = <0x1 0x1 0x1>;
				qcom,default-topology-index = <0x0>;
			};
		};
	};

	dsi_r66451_amoled_60hz_cmd_cphy: qcom,mdss_dsi_r66451_fhd_plus_60hz_cphy_cmd {
		qcom,mdss-dsi-panel-name = "r66451 amoled cmd mode dsi visionox panel with DSC";
		qcom,mdss-dsi-panel-type = "dsi_cmd_mode";
		qcom,mdss-dsi-panel-physical-type = "oled";
		qcom,mdss-dsi-virtual-channel-id = <0x0>;
		qcom,mdss-dsi-stream = <0x0>;
		qcom,mdss-dsi-bpp = <0x18>;
		qcom,mdss-dsi-border-color = <0x0>;
		qcom,dsi-ctrl-num = <0x0>;
		qcom,dsi-phy-num = <0x0>;
		qcom,mdss-dsi-traffic-mode = "non_burst_sync_event";
		qcom,mdss-dsi-bllp-eof-power-mode;
		qcom,mdss-dsi-bllp-power-mode;
		qcom,mdss-dsi-lane-0-state;
		qcom,mdss-dsi-lane-1-state;
		qcom,mdss-dsi-lane-2-state;
		qcom,mdss-dsi-dma-trigger = "trigger_sw";
		qcom,mdss-dsi-mdp-trigger = "none";
		qcom,mdss-dsi-reset-sequence = <0x1 0xa 0x0 0xa 0x1 0xa>;
		qcom,mdss-dsi-tx-eot-append;
		qcom,mdss-dsi-rx-eot-ignore;
		qcom,mdss-dsi-te-pin-select = <0x1>;
		qcom,mdss-dsi-wr-mem-start = <0x2c>;
		qcom,mdss-dsi-wr-mem-continue = <0x3c>;
		qcom,mdss-dsi-te-dcs-command = <0x1>;
		qcom,mdss-dsi-te-check-enable;
		qcom,mdss-dsi-te-using-te-pin;
		qcom,panel-cphy-mode;
		qcom,dsi-select-clocks = "mux_byte_clk0", "mux_pixel_clk0", "cphy_byte_clk0", "cphy_pixel_clk0";
		qcom,dsi-dyn-clk-enable;
		qcom,dsi-dyn-clk-list = <0x23cd3c00 0x23a70bc0 0x2380db80>;
		qcom,esd-check-enabled;
		qcom,mdss-dsi-panel-status-check-mode = "reg_read";
		qcom,mdss-dsi-panel-status-command = <0x6010001 0x10a>;
		qcom,mdss-dsi-panel-status-command-state = "dsi_lp_mode";
		qcom,mdss-dsi-panel-status-value = <0x1c>;
		qcom,mdss-dsi-panel-status-read-length = <0x1>;

		qcom,mdss-dsi-display-timings {

			timing@0 {
				qcom,mdss-dsi-panel-framerate = <0x3c>;
				qcom,mdss-dsi-panel-width = <0x438>;
				qcom,mdss-dsi-panel-height = <0x924>;
				qcom,mdss-dsi-h-front-porch = <0x60>;
				qcom,mdss-dsi-h-back-porch = <0x28>;
				qcom,mdss-dsi-h-pulse-width = <0x20>;
				qcom,mdss-dsi-h-sync-skew = <0x0>;
				qcom,mdss-dsi-v-back-porch = <0x4>;
				qcom,mdss-dsi-v-front-porch = <0x19>;
				qcom,mdss-dsi-v-pulse-width = <0x1>;
				qcom,mdss-dsi-h-left-border = <0x0>;
				qcom,mdss-dsi-h-right-border = <0x0>;
				qcom,mdss-dsi-v-top-border = <0x0>;
				qcom,mdss-dsi-v-bottom-border = <0x0>;
				qcom,mdss-dsi-panel-jitter = <0x4 0x1>;
				qcom,mdss-dsi-on-command = [39 01 00 00 00 00 02 b0 04 39 01 00 00 00 00 03 b4 20 1c 39 01 00 00 00 00 0d b6 6c 00 06 23 af 13 1a 05 04 fa 05 20 39 01 00 00 00 00 02 b0 00 39 01 00 00 00 00 02 d1 0b 39 01 00 00 00 00 0c c2 09 24 0c 00 00 10 04 a0 00 09 40 39 01 00 00 00 00 2c c4 00 00 00 00 00 00 00 00 0d 00 00 05 00 00 00 36 00 01 00 00 00 00 00 00 00 00 00 00 00 22 00 00 00 00 11 00 00 0c 00 00 00 00 30 39 01 00 00 00 00 86 cf 64 0b 00 22 00 cd 03 33 04 00 0b 77 01 01 01 02 02 03 03 04 04 04 04 05 00 00 00 3b 00 3b 01 64 01 64 01 64 01 64 01 64 01 64 03 ff 03 ff 03 ff 00 00 00 3b 00 3b 01 64 01 64 01 64 01 64 01 64 01 64 03 ff 03 ff 03 ff 01 62 01 62 01 62 01 62 01 62 01 62 01 62 01 62 01 62 01 62 01 62 01 62 19 19 19 19 19 19 19 19 19 19 19 19 00 00 00 43 00 43 01 98 01 98 06 61 06 61 0f f6 0f f6 0f f6 0f f6 0f f6 19 39 01 00 00 00 00 0d d0 44 44 b2 28 00 28 5a 00 5a 0d 17 01 39 01 00 00 00 00 09 d1 05 00 21 02 24 19 24 2d 39 01 00 00 00 00 15 d3 45 00 00 01 13 15 00 15 07 0f 77 77 77 37 b2 11 00 a0 3c 95 39 01 00 00 00 00 1a d7 00 b9 40 00 40 00 00 e0 0e 00 40 00 00 00 00 00 00 19 40 00 00 00 00 e0 0e 39 01 00 00 00 00 34 d8 00 00 00 00 00 00 00 00 00 3c 00 3c 00 3c 00 3c 00 3c 05 00 00 00 00 00 00 00 00 00 0e 00 0e 00 00 00 00 00 00 00 00 00 00 00 00 00 0e 00 36 00 0e 00 30 39 01 00 00 00 00 2b df 50 42 58 81 2d 00 00 00 00 00 00 6b 00 00 00 00 00 00 00 00 21 00 ff d4 0e 00 00 00 00 00 20 00 53 18 20 00 00 00 00 00 00 00 39 01 00 00 00 00 03 eb 8b 8b 39 01 00 00 00 00 02 f7 01 39 01 00 00 00 00 02 b0 80 39 01 00 00 00 00 0a e4 34 b4 00 00 00 3b 08 04 9a 39 01 00 00 00 00 02 e6 00 39 01 00 00 00 00 02 b0 04 39 01 00 00 00 00 03 df 50 40 39 01 00 00 00 00 06 f3 50 00 00 00 00 39 01 00 00 00 00 02 f2 11 39 01 00 00 00 00 06 f3 01 00 00 00 01 39 01 00 00 00 00 03 f4 00 02 39 01 00 00 00 00 02 f2 19 39 01 00 00 00 00 03 df 50 42 39 01 00 00 00 00 03 51 0f ff 39 01 00 00 00 00 02 35 00 39 01 00 00 00 00 05 2a 00 00 04 37 39 01 00 00 00 00 05 2b 00 00 09 23 05 01 00 00 78 00 01 11 05 01 00 00 00 00 01 29];
				qcom,mdss-dsi-off-command = [05 01 00 00 14 00 02 28 00 05 01 00 00 78 00 02 10 00];
				qcom,mdss-dsi-on-command-state = "dsi_lp_mode";
				qcom,mdss-dsi-off-command-state = "dsi_hs_mode";
				qcom,mdss-dsi-h-sync-pulse = <0x0>;
				qcom,compression-mode = "dsc";
				qcom,mdss-dsc-slice-height = <0x14>;
				qcom,mdss-dsc-slice-width = <0x21c>;
				qcom,mdss-dsc-slice-per-pkt = <0x2>;
				qcom,mdss-dsc-bit-per-component = <0x8>;
				qcom,mdss-dsc-bit-per-pixel = <0x8>;
				qcom,mdss-dsc-block-prediction-enable;
				qcom,mdss-dsi-panel-phy-timings = [00 00 00 00 1d 13 03 19 02 02 04 00 00 00];
				qcom,display-topology = <0x1 0x1 0x1>;
				qcom,default-topology-index = <0x0>;
			};
		};
	};

	dsi_r66451_amoled_90hz_cmd_cphy: qcom,mdss_dsi_r66451_fhd_plus_90hz_cphy_cmd {
		qcom,mdss-dsi-panel-name = "r66451 amoled cmd mode dsi visionox panel with DSC";
		qcom,mdss-dsi-panel-type = "dsi_cmd_mode";
		qcom,mdss-dsi-panel-physical-type = "oled";
		qcom,mdss-dsi-virtual-channel-id = <0x0>;
		qcom,mdss-dsi-stream = <0x0>;
		qcom,mdss-dsi-bpp = <0x18>;
		qcom,mdss-dsi-border-color = <0x0>;
		qcom,dsi-ctrl-num = <0x0>;
		qcom,dsi-phy-num = <0x0>;
		qcom,mdss-dsi-traffic-mode = "non_burst_sync_event";
		qcom,mdss-dsi-bllp-eof-power-mode;
		qcom,mdss-dsi-bllp-power-mode;
		qcom,mdss-dsi-lane-0-state;
		qcom,mdss-dsi-lane-1-state;
		qcom,mdss-dsi-lane-2-state;
		qcom,mdss-dsi-dma-trigger = "trigger_sw";
		qcom,mdss-dsi-mdp-trigger = "none";
		qcom,mdss-dsi-reset-sequence = <0x1 0xa 0x0 0xa 0x1 0xa>;
		qcom,mdss-dsi-tx-eot-append;
		qcom,mdss-dsi-rx-eot-ignore;
		qcom,mdss-dsi-te-pin-select = <0x1>;
		qcom,mdss-dsi-wr-mem-start = <0x2c>;
		qcom,mdss-dsi-wr-mem-continue = <0x3c>;
		qcom,mdss-dsi-te-dcs-command = <0x1>;
		qcom,mdss-dsi-te-check-enable;
		qcom,mdss-dsi-te-using-te-pin;
		qcom,panel-cphy-mode;
		qcom,dsi-select-clocks = "mux_byte_clk0", "mux_pixel_clk0", "cphy_byte_clk0", "cphy_pixel_clk0";
		qcom,esd-check-enabled;
		qcom,mdss-dsi-panel-status-check-mode = "reg_read";
		qcom,mdss-dsi-panel-status-command = <0x6010001 0x10a>;
		qcom,mdss-dsi-panel-status-command-state = "dsi_lp_mode";
		qcom,mdss-dsi-panel-status-value = <0x1c>;
		qcom,mdss-dsi-panel-status-read-length = <0x1>;
		qcom,panel-supply-entries = <&dsi_panel_pwr_supply_amoled>;
		qcom,mdss-dsi-bl-pmic-control-type = "bl_ctrl_dcs";
		qcom,mdss-dsi-bl-min-level = <0x1>;
		qcom,mdss-dsi-bl-max-level = <0xfff>;
		qcom,mdss-brightness-max-level = <0xff>;
		qcom,mdss-dsi-bl-inverted-dbv;
		qcom,platform-reset-gpio = <&tlmm 0x2c 0x0>;

		qcom,mdss-dsi-display-timings {

			timing@0 {
				qcom,mdss-dsi-panel-framerate = <0x5a>;
				qcom,mdss-dsi-panel-width = <0x438>;
				qcom,mdss-dsi-panel-height = <0x924>;
				qcom,mdss-dsi-h-front-porch = <0x60>;
				qcom,mdss-dsi-h-back-porch = <0x28>;
				qcom,mdss-dsi-h-pulse-width = <0x20>;
				qcom,mdss-dsi-h-sync-skew = <0x0>;
				qcom,mdss-dsi-v-back-porch = <0x4>;
				qcom,mdss-dsi-v-front-porch = <0x19>;
				qcom,mdss-dsi-v-pulse-width = <0x1>;
				qcom,mdss-dsi-h-left-border = <0x0>;
				qcom,mdss-dsi-h-right-border = <0x0>;
				qcom,mdss-dsi-v-top-border = <0x0>;
				qcom,mdss-dsi-v-bottom-border = <0x0>;
				qcom,mdss-dsi-panel-jitter = <0x4 0x1>;
				qcom,mdss-dsi-on-command = <0x39010000 0x2b0 0x80390100 0x2 0xe6003901 0x0 0x2b00439 0x1000000 0x3b420 0x1c390100 0xd 0xb66c0006 0x23af131a 0x504fa05 0x20390100 0xc 0xc209240c 0x1000 0x940 0x39010000 0x1ad7 0xb94000 0x400000e0 0xe004000 0x0 0x194000 0xe0 0xe390100 0x86 0xcf640b00 0x2200cd03 0x3304000b 0x77010101 0x2020303 0x4040404 0x5000000 0x3b003b01 0x64016401 0x64016401 0x64016403 0xff03ff03 0xff000000 0x3b003b01 0x64016401 0x64016401 0x64016403 0xff03ff03 0xff016201 0x62016201 0x62016201 0x62016201 0x62016201 0x62016201 0x62191919 0x19191919 0x19191919 0x19000000 0x43004301 0x98019806 0x6106610f 0xf60ff60f 0xf60ff60f 0xf6193901 0x0 0x9d10500 0x21022419 0x242d3901 0x0 0x3eb8b8b 0x39010000 0x2f7 0x1390100 0x3 0xdf504039 0x1000000 0x6f350 0x0 0x39010000 0x2f2 0x11390100 0x6 0xf3010000 0x13901 0x0 0x3f40002 0x39010000 0x2f2 0x19390100 0x3 0xdf504239 0x1000000 0x23500 0x39010000 0x52a 0x437 0x39010000 0x52b 0x923 0x5010000 0x78000111 0x5010000 0x129>;
				qcom,mdss-dsi-off-command = [05 01 00 00 14 00 02 28 00 05 01 00 00 78 00 02 10 00];
				qcom,mdss-dsi-on-command-state = "dsi_lp_mode";
				qcom,mdss-dsi-off-command-state = "dsi_hs_mode";
				qcom,mdss-dsi-h-sync-pulse = <0x0>;
				qcom,compression-mode = "dsc";
				qcom,mdss-dsc-slice-height = <0x14>;
				qcom,mdss-dsc-slice-width = <0x21c>;
				qcom,mdss-dsc-slice-per-pkt = <0x2>;
				qcom,mdss-dsc-bit-per-component = <0x8>;
				qcom,mdss-dsc-bit-per-pixel = <0x8>;
				qcom,mdss-dsc-block-prediction-enable;
				qcom,mdss-dsi-panel-phy-timings = [00 00 00 00 1e 17 04 19 03 02 04 00 00 00];
				qcom,display-topology = <0x1 0x1 0x1>;
				qcom,default-topology-index = <0x0>;
			};
		};
	};

	dsi_r66451_amoled_120hz_cmd_cphy: qcom,mdss_dsi_r66451_fhd_plus_120hz_cphy_cmd {
		qcom,mdss-dsi-panel-name = "r66451 amoled cmd mode dsi visionox panel with DSC";
		qcom,mdss-dsi-panel-type = "dsi_cmd_mode";
		qcom,mdss-dsi-panel-physical-type = "oled";
		qcom,mdss-dsi-virtual-channel-id = <0x0>;
		qcom,mdss-dsi-stream = <0x0>;
		qcom,mdss-dsi-bpp = <0x18>;
		qcom,mdss-dsi-border-color = <0x0>;
		qcom,dsi-ctrl-num = <0x0>;
		qcom,dsi-phy-num = <0x0>;
		qcom,mdss-dsi-traffic-mode = "non_burst_sync_event";
		qcom,mdss-dsi-bllp-eof-power-mode;
		qcom,mdss-dsi-bllp-power-mode;
		qcom,mdss-dsi-lane-0-state;
		qcom,mdss-dsi-lane-1-state;
		qcom,mdss-dsi-lane-2-state;
		qcom,mdss-dsi-dma-trigger = "trigger_sw";
		qcom,mdss-dsi-mdp-trigger = "none";
		qcom,mdss-dsi-reset-sequence = <0x1 0xa 0x0 0xa 0x1 0xa>;
		qcom,mdss-dsi-tx-eot-append;
		qcom,mdss-dsi-rx-eot-ignore;
		qcom,mdss-dsi-te-pin-select = <0x1>;
		qcom,mdss-dsi-wr-mem-start = <0x2c>;
		qcom,mdss-dsi-wr-mem-continue = <0x3c>;
		qcom,mdss-dsi-te-dcs-command = <0x1>;
		qcom,mdss-dsi-te-check-enable;
		qcom,mdss-dsi-te-using-te-pin;
		qcom,panel-cphy-mode;
		qcom,dsi-select-clocks = "mux_byte_clk0", "mux_pixel_clk0", "cphy_byte_clk0", "cphy_pixel_clk0";
		qcom,esd-check-enabled;
		qcom,mdss-dsi-panel-status-check-mode = "reg_read";
		qcom,mdss-dsi-panel-status-command = <0x6010001 0x10a>;
		qcom,mdss-dsi-panel-status-command-state = "dsi_lp_mode";
		qcom,mdss-dsi-panel-status-value = <0x1c>;
		qcom,mdss-dsi-panel-status-read-length = <0x1>;
		qcom,panel-supply-entries = <&dsi_panel_pwr_supply_amoled>;
		qcom,mdss-dsi-bl-pmic-control-type = "bl_ctrl_dcs";
		qcom,mdss-dsi-bl-min-level = <0x1>;
		qcom,mdss-dsi-bl-max-level = <0xfff>;
		qcom,mdss-brightness-max-level = <0xff>;
		qcom,mdss-dsi-bl-inverted-dbv;
		qcom,platform-reset-gpio = <&tlmm 0x2c 0x0>;

		qcom,mdss-dsi-display-timings {

			timing@0 {
				qcom,mdss-dsi-panel-framerate = <0x3c>;
				qcom,mdss-dsi-panel-width = <0x438>;
				qcom,mdss-dsi-panel-height = <0x924>;
				qcom,mdss-dsi-h-front-porch = <0x60>;
				qcom,mdss-dsi-h-back-porch = <0x28>;
				qcom,mdss-dsi-h-pulse-width = <0x20>;
				qcom,mdss-dsi-h-sync-skew = <0x0>;
				qcom,mdss-dsi-v-back-porch = <0x4>;
				qcom,mdss-dsi-v-front-porch = <0x19>;
				qcom,mdss-dsi-v-pulse-width = <0x1>;
				qcom,mdss-dsi-h-left-border = <0x0>;
				qcom,mdss-dsi-h-right-border = <0x0>;
				qcom,mdss-dsi-v-top-border = <0x0>;
				qcom,mdss-dsi-v-bottom-border = <0x0>;
				qcom,mdss-dsi-panel-jitter = <0x4 0x1>;
				qcom,mdss-dsi-timing-switch-command = [39 01 00 00 00 00 02 b0 00 39 01 00 00 00 00 1a c2 09 24 0c 00 00 0c 09 3c 00 09 3c 00 00 00 00 00 00 00 00 00 00 00 30 00 6c];
				qcom,mdss-dsi-on-command = [39 01 00 00 00 00 02 b0 00 39 01 00 00 00 00 0c c2 09 24 0c 00 00 0c 00 00 00 09 3c 39 01 00 00 00 00 1a d7 00 b9 3c 00 40 04 00 a0 0a 00 40 00 00 00 00 00 00 19 3c 00 40 04 00 a0 0a 39 01 00 00 00 00 02 b0 80 39 01 00 00 00 00 14 de 40 00 18 00 18 00 18 00 18 10 00 18 00 18 00 18 02 00 00 39 01 00 00 00 00 02 b0 04 39 01 00 00 00 00 03 e8 00 02 39 01 00 00 00 00 03 e4 00 08 39 01 00 00 00 00 03 b4 20 1c 39 01 00 00 00 00 0d b6 6c 00 06 23 af 13 1a 05 04 fa 05 20 39 01 00 00 00 00 02 b0 00 39 01 00 00 00 00 32 c4 00 00 00 00 00 00 00 00 10 00 00 02 00 00 00 29 00 01 00 00 00 00 00 00 00 00 00 00 00 22 00 00 00 00 11 00 00 0c 00 00 00 00 30 00 00 00 00 00 00 39 01 00 00 00 00 86 cf 64 0b 00 22 00 cd 03 33 04 00 0b 77 01 01 01 02 02 03 03 04 04 04 04 05 00 00 00 3b 00 3b 01 64 01 64 01 64 01 64 01 64 01 64 03 ff 03 ff 03 ff 00 00 00 3b 00 3b 01 64 01 64 01 64 01 64 01 64 01 64 03 ff 03 ff 03 ff 01 62 01 62 01 62 01 62 01 62 01 62 01 62 01 62 01 62 01 62 01 62 01 62 19 19 19 19 19 19 19 19 19 19 19 19 00 00 00 43 00 43 01 98 01 98 06 61 06 61 0f f6 0f f6 0f f6 0f f6 0f f6 19 39 01 00 00 00 00 09 d1 05 00 21 02 24 19 24 2d 39 01 00 00 00 00 15 d3 49 00 00 01 1a 15 00 15 07 0f 77 77 77 37 b2 11 00 a0 3c 9a 39 01 00 00 00 00 1a d7 00 b9 34 00 40 04 00 f0 0f 00 40 00 00 00 00 00 00 19 34 00 40 04 00 f0 0f 39 01 00 00 00 00 34 d8 00 00 00 00 00 00 00 00 00 3a 00 3a 00 3a 00 3a 00 3a 05 00 00 00 00 00 00 00 00 00 0f 00 0f 00 00 00 00 00 00 00 00 00 00 00 00 00 0f 00 2f 00 0f 00 20 39 01 00 00 00 00 2b df 50 42 58 81 2d 00 00 00 00 00 00 6b 00 00 00 00 00 00 00 00 01 0f ff d4 0e 00 00 00 00 00 00 0f 53 18 00 0f 00 00 00 00 00 00 39 01 00 00 00 00 03 eb 8b 8b 39 01 00 00 00 00 02 f7 01 39 01 00 00 00 00 02 b0 80 39 01 00 00 00 00 0a e4 34 b4 00 00 00 30 04 0c e2 39 01 00 00 00 00 02 e6 00 39 01 00 00 00 00 02 b0 04 39 01 00 00 00 00 03 df 50 40 39 01 00 00 00 00 06 f3 50 00 00 00 00 39 01 00 00 00 00 02 f2 11 39 01 00 00 00 00 06 f3 01 00 00 00 01 39 01 00 00 00 00 03 f4 00 02 39 01 00 00 00 00 02 f2 19 39 01 00 00 00 00 03 df 50 42 39 01 00 00 00 00 02 35 00 39 01 00 00 00 00 05 2a 00 00 04 37 39 01 00 00 00 00 05 2b 00 00 09 23 05 01 00 00 78 00 01 11 05 01 00 00 00 00 01 29 39 01 00 00 00 00 02 b0 00 39 01 00 00 00 00 1a c2 09 24 0c 00 00 0c 09 3c 00 09 3c 00 00 00 00 00 00 00 00 00 00 00 30 00 6c];
				qcom,mdss-dsi-off-command = [05 01 00 00 14 00 02 28 00 05 01 00 00 78 00 02 10 00];
				qcom,mdss-dsi-on-command-state = "dsi_lp_mode";
				qcom,mdss-dsi-off-command-state = "dsi_hs_mode";
				qcom,mdss-dsi-h-sync-pulse = <0x0>;
				qcom,compression-mode = "dsc";
				qcom,mdss-dsc-slice-height = <0x14>;
				qcom,mdss-dsc-slice-width = <0x21c>;
				qcom,mdss-dsc-slice-per-pkt = <0x2>;
				qcom,mdss-dsc-bit-per-component = <0x8>;
				qcom,mdss-dsc-bit-per-pixel = <0x8>;
				qcom,mdss-dsc-block-prediction-enable;
				qcom,mdss-dsi-panel-phy-timings = [00 00 00 00 1d 13 03 19 02 02 04 00 00 00];
				qcom,display-topology = <0x1 0x1 0x1>;
				qcom,default-topology-index = <0x0>;
			};

			timing@1 {
				qcom,mdss-dsi-panel-framerate = <0x5a>;
				qcom,mdss-dsi-panel-width = <0x438>;
				qcom,mdss-dsi-panel-height = <0x924>;
				qcom,mdss-dsi-h-front-porch = <0x60>;
				qcom,mdss-dsi-h-back-porch = <0x28>;
				qcom,mdss-dsi-h-pulse-width = <0x20>;
				qcom,mdss-dsi-h-sync-skew = <0x0>;
				qcom,mdss-dsi-v-back-porch = <0x4>;
				qcom,mdss-dsi-v-front-porch = <0x19>;
				qcom,mdss-dsi-v-pulse-width = <0x1>;
				qcom,mdss-dsi-h-left-border = <0x0>;
				qcom,mdss-dsi-h-right-border = <0x0>;
				qcom,mdss-dsi-v-top-border = <0x0>;
				qcom,mdss-dsi-v-bottom-border = <0x0>;
				qcom,mdss-dsi-panel-jitter = <0x4 0x1>;
				qcom,mdss-dsi-timing-switch-command = [39 01 00 00 00 00 02 b0 00 39 01 00 00 00 00 1a c2 09 24 0c 00 00 0c 03 14 00 09 3c 00 00 00 00 00 00 00 00 00 00 00 30 00 6c];
				qcom,mdss-dsi-on-command = [39 01 00 00 00 00 02 b0 00 39 01 00 00 00 00 0c c2 09 24 0c 00 00 0c 00 00 00 09 3c 39 01 00 00 00 00 1a d7 00 b9 3c 00 40 04 00 a0 0a 00 40 00 00 00 00 00 00 19 3c 00 40 04 00 a0 0a 39 01 00 00 00 00 02 b0 80 39 01 00 00 00 00 14 de 40 00 18 00 18 00 18 00 18 10 00 18 00 18 00 18 02 00 00 39 01 00 00 00 00 02 b0 04 39 01 00 00 00 00 03 e8 00 02 39 01 00 00 00 00 03 e4 00 08 39 01 00 00 00 00 03 b4 20 1c 39 01 00 00 00 00 0d b6 6c 00 06 23 af 13 1a 05 04 fa 05 20 39 01 00 00 00 00 02 b0 00 39 01 00 00 00 00 32 c4 00 00 00 00 00 00 00 00 10 00 00 02 00 00 00 29 00 01 00 00 00 00 00 00 00 00 00 00 00 22 00 00 00 00 11 00 00 0c 00 00 00 00 30 00 00 00 00 00 00 39 01 00 00 00 00 86 cf 64 0b 00 22 00 cd 03 33 04 00 0b 77 01 01 01 02 02 03 03 04 04 04 04 05 00 00 00 3b 00 3b 01 64 01 64 01 64 01 64 01 64 01 64 03 ff 03 ff 03 ff 00 00 00 3b 00 3b 01 64 01 64 01 64 01 64 01 64 01 64 03 ff 03 ff 03 ff 01 62 01 62 01 62 01 62 01 62 01 62 01 62 01 62 01 62 01 62 01 62 01 62 19 19 19 19 19 19 19 19 19 19 19 19 00 00 00 43 00 43 01 98 01 98 06 61 06 61 0f f6 0f f6 0f f6 0f f6 0f f6 19 39 01 00 00 00 00 09 d1 05 00 21 02 24 19 24 2d 39 01 00 00 00 00 15 d3 49 00 00 01 1a 15 00 15 07 0f 77 77 77 37 b2 11 00 a0 3c 9a 39 01 00 00 00 00 1a d7 00 b9 34 00 40 04 00 f0 0f 00 40 00 00 00 00 00 00 19 34 00 40 04 00 f0 0f 39 01 00 00 00 00 34 d8 00 00 00 00 00 00 00 00 00 3a 00 3a 00 3a 00 3a 00 3a 05 00 00 00 00 00 00 00 00 00 0f 00 0f 00 00 00 00 00 00 00 00 00 00 00 00 00 0f 00 2f 00 0f 00 20 39 01 00 00 00 00 2b df 50 42 58 81 2d 00 00 00 00 00 00 6b 00 00 00 00 00 00 00 00 01 0f ff d4 0e 00 00 00 00 00 00 0f 53 18 00 0f 00 00 00 00 00 00 39 01 00 00 00 00 03 eb 8b 8b 39 01 00 00 00 00 02 f7 01 39 01 00 00 00 00 02 b0 80 39 01 00 00 00 00 0a e4 34 b4 00 00 00 30 04 0c e2 39 01 00 00 00 00 02 e6 00 39 01 00 00 00 00 02 b0 04 39 01 00 00 00 00 03 df 50 40 39 01 00 00 00 00 06 f3 50 00 00 00 00 39 01 00 00 00 00 02 f2 11 39 01 00 00 00 00 06 f3 01 00 00 00 01 39 01 00 00 00 00 03 f4 00 02 39 01 00 00 00 00 02 f2 19 39 01 00 00 00 00 03 df 50 42 39 01 00 00 00 00 02 35 00 39 01 00 00 00 00 05 2a 00 00 04 37 39 01 00 00 00 00 05 2b 00 00 09 23 05 01 00 00 78 00 01 11 05 01 00 00 00 00 01 29 39 01 00 00 00 00 02 b0 00 39 01 00 00 00 00 1a c2 09 24 0c 00 00 0c 03 14 00 09 3c 00 00 00 00 00 00 00 00 00 00 00 30 00 6c];
				qcom,mdss-dsi-off-command = [05 01 00 00 14 00 02 28 00 05 01 00 00 78 00 02 10 00];
				qcom,mdss-dsi-on-command-state = "dsi_lp_mode";
				qcom,mdss-dsi-off-command-state = "dsi_hs_mode";
				qcom,mdss-dsi-h-sync-pulse = <0x0>;
				qcom,compression-mode = "dsc";
				qcom,mdss-dsc-slice-height = <0x14>;
				qcom,mdss-dsc-slice-width = <0x21c>;
				qcom,mdss-dsc-slice-per-pkt = <0x2>;
				qcom,mdss-dsc-bit-per-component = <0x8>;
				qcom,mdss-dsc-bit-per-pixel = <0x8>;
				qcom,mdss-dsc-block-prediction-enable;
				qcom,mdss-dsi-panel-phy-timings = [00 00 00 00 1e 17 04 19 03 02 04 00 00 00];
				qcom,display-topology = <0x1 0x1 0x1>;
				qcom,default-topology-index = <0x0>;
			};

			timing@2 {
				qcom,mdss-dsi-panel-framerate = <0x78>;
				qcom,mdss-dsi-panel-width = <0x438>;
				qcom,mdss-dsi-panel-height = <0x924>;
				qcom,mdss-dsi-h-front-porch = <0x60>;
				qcom,mdss-dsi-h-back-porch = <0x28>;
				qcom,mdss-dsi-h-pulse-width = <0x20>;
				qcom,mdss-dsi-h-sync-skew = <0x0>;
				qcom,mdss-dsi-v-back-porch = <0x4>;
				qcom,mdss-dsi-v-front-porch = <0x19>;
				qcom,mdss-dsi-v-pulse-width = <0x1>;
				qcom,mdss-dsi-h-left-border = <0x0>;
				qcom,mdss-dsi-h-right-border = <0x0>;
				qcom,mdss-dsi-v-top-border = <0x0>;
				qcom,mdss-dsi-v-bottom-border = <0x0>;
				qcom,mdss-dsi-panel-jitter = <0x4 0x1>;
				qcom,mdss-dsi-timing-switch-command = [39 01 00 00 00 00 02 b0 00 39 01 00 00 00 00 1a c2 09 24 0c 00 00 0c 00 00 00 09 3c 00 00 00 00 00 00 00 00 00 00 00 30 00 6c];
				qcom,mdss-dsi-on-command = [39 01 00 00 00 00 02 b0 00 39 01 00 00 00 00 0c c2 09 24 0c 00 00 0c 00 00 00 09 3c 39 01 00 00 00 00 1a d7 00 b9 3c 00 40 04 00 a0 0a 00 40 00 00 00 00 00 00 19 3c 00 40 04 00 a0 0a 39 01 00 00 00 00 02 b0 80 39 01 00 00 00 00 14 de 40 00 18 00 18 00 18 00 18 10 00 18 00 18 00 18 02 00 00 39 01 00 00 00 00 02 b0 04 39 01 00 00 00 00 03 e8 00 02 39 01 00 00 00 00 03 e4 00 08 39 01 00 00 00 00 03 b4 20 1c 39 01 00 00 00 00 0d b6 6c 00 06 23 af 13 1a 05 04 fa 05 20 39 01 00 00 00 00 02 b0 00 39 01 00 00 00 00 32 c4 00 00 00 00 00 00 00 00 10 00 00 02 00 00 00 29 00 01 00 00 00 00 00 00 00 00 00 00 00 22 00 00 00 00 11 00 00 0c 00 00 00 00 30 00 00 00 00 00 00 39 01 00 00 00 00 86 cf 64 0b 00 22 00 cd 03 33 04 00 0b 77 01 01 01 02 02 03 03 04 04 04 04 05 00 00 00 3b 00 3b 01 64 01 64 01 64 01 64 01 64 01 64 03 ff 03 ff 03 ff 00 00 00 3b 00 3b 01 64 01 64 01 64 01 64 01 64 01 64 03 ff 03 ff 03 ff 01 62 01 62 01 62 01 62 01 62 01 62 01 62 01 62 01 62 01 62 01 62 01 62 19 19 19 19 19 19 19 19 19 19 19 19 00 00 00 43 00 43 01 98 01 98 06 61 06 61 0f f6 0f f6 0f f6 0f f6 0f f6 19 39 01 00 00 00 00 09 d1 05 00 21 02 24 19 24 2d 39 01 00 00 00 00 15 d3 49 00 00 01 1a 15 00 15 07 0f 77 77 77 37 b2 11 00 a0 3c 9a 39 01 00 00 00 00 1a d7 00 b9 34 00 40 04 00 f0 0f 00 40 00 00 00 00 00 00 19 34 00 40 04 00 f0 0f 39 01 00 00 00 00 34 d8 00 00 00 00 00 00 00 00 00 3a 00 3a 00 3a 00 3a 00 3a 05 00 00 00 00 00 00 00 00 00 0f 00 0f 00 00 00 00 00 00 00 00 00 00 00 00 00 0f 00 2f 00 0f 00 20 39 01 00 00 00 00 2b df 50 42 58 81 2d 00 00 00 00 00 00 6b 00 00 00 00 00 00 00 00 01 0f ff d4 0e 00 00 00 00 00 00 0f 53 18 00 0f 00 00 00 00 00 00 39 01 00 00 00 00 03 eb 8b 8b 39 01 00 00 00 00 02 f7 01 39 01 00 00 00 00 02 b0 80 39 01 00 00 00 00 0a e4 34 b4 00 00 00 30 04 0c e2 39 01 00 00 00 00 02 e6 00 39 01 00 00 00 00 02 b0 04 39 01 00 00 00 00 03 df 50 40 39 01 00 00 00 00 06 f3 50 00 00 00 00 39 01 00 00 00 00 02 f2 11 39 01 00 00 00 00 06 f3 01 00 00 00 01 39 01 00 00 00 00 03 f4 00 02 39 01 00 00 00 00 02 f2 19 39 01 00 00 00 00 03 df 50 42 39 01 00 00 00 00 02 35 00 39 01 00 00 00 00 05 2a 00 00 04 37 39 01 00 00 00 00 05 2b 00 00 09 23 05 01 00 00 78 00 01 11 05 01 00 00 00 00 01 29];
				qcom,mdss-dsi-off-command = [05 01 00 00 14 00 02 28 00 05 01 00 00 78 00 02 10 00];
				qcom,mdss-dsi-on-command-state = "dsi_lp_mode";
				qcom,mdss-dsi-off-command-state = "dsi_hs_mode";
				qcom,mdss-dsi-h-sync-pulse = <0x0>;
				qcom,compression-mode = "dsc";
				qcom,mdss-dsc-slice-height = <0x14>;
				qcom,mdss-dsc-slice-width = <0x21c>;
				qcom,mdss-dsc-slice-per-pkt = <0x2>;
				qcom,mdss-dsc-bit-per-component = <0x8>;
				qcom,mdss-dsc-bit-per-pixel = <0x8>;
				qcom,mdss-dsc-block-prediction-enable;
				qcom,mdss-dsi-panel-phy-timings = [00 00 00 00 20 1b 05 19 06 02 04 00 00 00];
				qcom,display-topology = <0x1 0x1 0x1>;
				qcom,default-topology-index = <0x0>;
			};
		};
	};

	dsi_r66451_amoled_120hz_video_cphy: qcom,mdss_dsi_r66451_fhd_plus_cphy_120hz_vid {
		qcom,mdss-dsi-panel-name = "r66451 amoled video mode dsi visionox panel with DSC";
		qcom,mdss-dsi-panel-type = "dsi_video_mode";
		qcom,mdss-dsi-panel-physical-type = "oled";
		qcom,dsi-ctrl-num = <0x0>;
		qcom,dsi-phy-num = <0x0>;
		qcom,mdss-dsi-virtual-channel-id = <0x0>;
		qcom,mdss-dsi-stream = <0x0>;
		qcom,mdss-dsi-bpp = <0x18>;
		qcom,mdss-dsi-border-color = <0x0>;
		qcom,mdss-dsi-traffic-mode = "non_burst_sync_event";
		qcom,mdss-dsi-bllp-eof-power-mode;
		qcom,mdss-dsi-bllp-power-mode;
		qcom,mdss-dsi-lane-0-state;
		qcom,mdss-dsi-lane-1-state;
		qcom,mdss-dsi-lane-2-state;
		qcom,mdss-dsi-dma-trigger = "trigger_sw";
		qcom,mdss-dsi-mdp-trigger = "none";
		qcom,mdss-dsi-reset-sequence = <0x1 0xa 0x0 0xa 0x1 0xa>;
		qcom,adjust-timer-wakeup-ms = <0x1>;
		qcom,panel-cphy-mode;
		qcom,dsi-select-clocks = "mux_byte_clk0", "mux_pixel_clk0", "cphy_byte_clk0", "cphy_pixel_clk0";
		qcom,dsi-supported-dfps-list = <0x78 0x5a 0x3c>;
		qcom,mdss-dsi-pan-enable-dynamic-fps;
		qcom,mdss-dsi-pan-fps-update = "dfps_immediate_porch_mode_vfp";
		qcom,esd-check-enabled;
		qcom,mdss-dsi-panel-status-check-mode = "reg_read";
		qcom,mdss-dsi-panel-status-command = <0x6010001 0x10a>;
		qcom,mdss-dsi-panel-status-command-state = "dsi_lp_mode";
		qcom,mdss-dsi-panel-status-value = <0x1c>;
		qcom,mdss-dsi-panel-status-read-length = <0x1>;

		qcom,mdss-dsi-display-timings {

			timing@0 {
				qcom,mdss-dsi-panel-framerate = <0x78>;
				qcom,mdss-dsi-panel-width = <0x438>;
				qcom,mdss-dsi-panel-height = <0x924>;
				qcom,mdss-dsi-h-front-porch = <0x60>;
				qcom,mdss-dsi-h-back-porch = <0x28>;
				qcom,mdss-dsi-h-pulse-width = <0x20>;
				qcom,mdss-dsi-h-sync-skew = <0x0>;
				qcom,mdss-dsi-v-back-porch = <0x4>;
				qcom,mdss-dsi-v-front-porch = <0x19>;
				qcom,mdss-dsi-v-pulse-width = <0x1>;
				qcom,mdss-dsi-h-left-border = <0x0>;
				qcom,mdss-dsi-h-right-border = <0x0>;
				qcom,mdss-dsi-v-top-border = <0x0>;
				qcom,mdss-dsi-v-bottom-border = <0x0>;
				qcom,mdss-dsi-on-command = [39 01 00 00 00 00 02 b0 00 39 01 00 00 00 00 02 b3 01 39 01 00 00 00 00 02 b0 04 39 01 00 00 00 00 03 e8 00 02 39 01 00 00 00 00 03 e4 00 08 39 01 00 00 00 00 03 b4 20 1c 39 01 00 00 00 00 0d b6 6c 00 06 23 af 13 1a 05 04 fa 05 20 39 01 00 00 00 00 02 b0 00 39 01 00 00 00 00 32 c4 00 00 00 00 00 00 00 00 10 00 00 02 00 00 00 29 00 01 00 00 00 00 00 00 00 00 00 00 00 22 00 00 00 00 11 00 00 0c 00 00 00 00 30 00 00 00 00 00 00 39 01 00 00 00 00 86 cf 64 0b 00 22 00 cd 03 33 04 00 0b 77 01 01 01 02 02 03 03 04 04 04 04 05 00 00 00 3b 00 3b 01 64 01 64 01 64 01 64 01 64 01 64 03 ff 03 ff 03 ff 00 00 00 3b 00 3b 01 64 01 64 01 64 01 64 01 64 01 64 03 ff 03 ff 03 ff 01 62 01 62 01 62 01 62 01 62 01 62 01 62 01 62 01 62 01 62 01 62 01 62 19 19 19 19 19 19 19 19 19 19 19 19 00 00 00 43 00 43 01 98 01 98 06 61 06 61 0f f6 0f f6 0f f6 0f f6 0f f6 19 39 01 00 00 00 00 09 d1 05 00 21 02 24 19 24 2d 39 01 00 00 00 00 15 d3 49 00 00 01 1a 15 00 15 07 0f 77 77 77 37 b2 11 00 a0 3c 9a 39 01 00 00 00 00 1a d7 00 b9 34 00 40 04 00 f0 0f 00 40 00 00 00 00 00 00 19 34 00 40 04 00 f0 0f 39 01 00 00 00 00 34 d8 00 00 00 00 00 00 00 00 00 3a 00 3a 00 3a 00 3a 00 3a 05 00 00 00 00 00 00 00 00 00 0f 00 0f 00 00 00 00 00 00 00 00 00 00 00 00 00 0f 00 2f 00 0f 00 20 39 01 00 00 00 00 2b df 50 42 58 81 2d 00 00 00 00 00 00 6b 00 00 00 00 00 00 00 00 01 0f ff d4 0e 00 00 00 00 00 00 0f 53 18 00 0f 00 00 00 00 00 00 39 01 00 00 00 00 03 eb 8b 8b 39 01 00 00 00 00 02 f7 01 39 01 00 00 00 00 02 b0 80 39 01 00 00 00 00 0a e4 34 b4 00 00 00 30 04 0c e2 39 01 00 00 00 00 02 e6 00 39 01 00 00 00 00 02 b0 04 39 01 00 00 00 00 03 df 50 40 39 01 00 00 00 00 06 f3 50 00 00 00 00 39 01 00 00 00 00 02 f2 11 39 01 00 00 00 00 06 f3 01 00 00 00 01 39 01 00 00 00 00 03 f4 00 02 39 01 00 00 00 00 02 f2 19 39 01 00 00 00 00 03 df 50 42 39 01 00 00 00 00 05 2a 00 00 04 37 39 01 00 00 00 00 05 2b 00 00 09 23 05 01 00 00 78 00 01 11 05 01 00 00 00 00 01 29];
				qcom,mdss-dsi-off-command = [05 01 00 00 14 00 02 28 00 05 01 00 00 78 00 02 10 00];
				qcom,mdss-dsi-on-command-state = "dsi_lp_mode";
				qcom,mdss-dsi-off-command-state = "dsi_hs_mode";
				qcom,mdss-dsi-h-sync-pulse = <0x0>;
				qcom,compression-mode = "dsc";
				qcom,mdss-dsc-slice-height = <0x14>;
				qcom,mdss-dsc-slice-width = <0x21c>;
				qcom,mdss-dsc-slice-per-pkt = <0x2>;
				qcom,mdss-dsc-bit-per-component = <0x8>;
				qcom,mdss-dsc-bit-per-pixel = <0x8>;
				qcom,mdss-dsc-block-prediction-enable;
				qcom,mdss-dsi-panel-phy-timings = [00 00 00 00 20 1b 05 19 06 02 04 00 00 00];
				qcom,display-topology = <0x1 0x1 0x1>;
				qcom,default-topology-index = <0x0>;
			};
		};
	};

	dsi_r66451_amoled_144hz_cmd_cphy: qcom,mdss_dsi_r66451_fhd_plus_144hz_cphy_cmd {
		qcom,mdss-dsi-panel-name = "r66451 amoled cmd mode dsi visionox panel with DSC";
		qcom,mdss-dsi-panel-type = "dsi_cmd_mode";
		qcom,mdss-dsi-panel-physical-type = "oled";
		qcom,mdss-dsi-virtual-channel-id = <0x0>;
		qcom,mdss-dsi-stream = <0x0>;
		qcom,mdss-dsi-bpp = <0x18>;
		qcom,mdss-dsi-border-color = <0x0>;
		qcom,dsi-ctrl-num = <0x0>;
		qcom,dsi-phy-num = <0x0>;
		qcom,mdss-dsi-traffic-mode = "non_burst_sync_event";
		qcom,mdss-dsi-bllp-eof-power-mode;
		qcom,mdss-dsi-bllp-power-mode;
		qcom,mdss-dsi-lane-0-state;
		qcom,mdss-dsi-lane-1-state;
		qcom,mdss-dsi-lane-2-state;
		qcom,mdss-dsi-dma-trigger = "trigger_sw";
		qcom,mdss-dsi-mdp-trigger = "none";
		qcom,mdss-dsi-reset-sequence = <0x1 0xa 0x0 0xa 0x1 0xa>;
		qcom,mdss-dsi-tx-eot-append;
		qcom,mdss-dsi-rx-eot-ignore;
		qcom,mdss-dsi-te-pin-select = <0x1>;
		qcom,mdss-dsi-wr-mem-start = <0x2c>;
		qcom,mdss-dsi-wr-mem-continue = <0x3c>;
		qcom,mdss-dsi-te-dcs-command = <0x1>;
		qcom,mdss-dsi-te-check-enable;
		qcom,mdss-dsi-te-using-te-pin;
		qcom,panel-cphy-mode;
		qcom,dsi-select-clocks = "mux_byte_clk0", "mux_pixel_clk0", "cphy_byte_clk0", "cphy_pixel_clk0";
		qcom,esd-check-enabled;
		qcom,mdss-dsi-panel-status-check-mode = "reg_read";
		qcom,mdss-dsi-panel-status-command = <0x6010001 0x10a>;
		qcom,mdss-dsi-panel-status-command-state = "dsi_lp_mode";
		qcom,mdss-dsi-panel-status-value = <0x1c>;
		qcom,mdss-dsi-panel-status-read-length = <0x1>;
		qcom,panel-supply-entries = <&dsi_panel_pwr_supply_amoled>;
		qcom,mdss-dsi-bl-pmic-control-type = "bl_ctrl_dcs";
		qcom,mdss-dsi-bl-min-level = <0x1>;
		qcom,mdss-dsi-bl-max-level = <0xfff>;
		qcom,mdss-brightness-max-level = <0xff>;
		qcom,mdss-dsi-bl-inverted-dbv;
		qcom,platform-reset-gpio = <&tlmm 0x2c 0x0>;

		qcom,mdss-dsi-display-timings {

			timing@0 {
				qcom,mdss-dsi-panel-framerate = <0x90>;
				qcom,mdss-dsi-panel-width = <0x438>;
				qcom,mdss-dsi-panel-height = <0x924>;
				qcom,mdss-dsi-h-front-porch = <0x60>;
				qcom,mdss-dsi-h-back-porch = <0x28>;
				qcom,mdss-dsi-h-pulse-width = <0x20>;
				qcom,mdss-dsi-h-sync-skew = <0x0>;
				qcom,mdss-dsi-v-back-porch = <0x4>;
				qcom,mdss-dsi-v-front-porch = <0x19>;
				qcom,mdss-dsi-v-pulse-width = <0x1>;
				qcom,mdss-dsi-h-left-border = <0x0>;
				qcom,mdss-dsi-h-right-border = <0x0>;
				qcom,mdss-dsi-v-top-border = <0x0>;
				qcom,mdss-dsi-v-bottom-border = <0x0>;
				qcom,mdss-dsi-panel-jitter = <0x4 0x1>;
				qcom,mdss-dsi-timing-switch-command = <0x39010000 0xdd0 0x4444b228 0x285a00 0x5a030d01 0x39010000 0x1ac2 0x9240c00 0x40000 0x93400 0x0 0x0 0x3000 0x6c390100 0x34 0xd8000000 0x0 0x3000 0x30003000 0x30003005 0x0 0x0 0xf000f 0x0 0x0 0x0 0xf002f 0xf0020>;
				qcom,mdss-dsi-on-command = [39 01 00 00 00 00 02 b0 04 39 01 00 00 00 00 03 e8 00 02 39 01 00 00 00 00 03 e4 00 08 39 01 00 00 00 00 03 b4 20 1c 39 01 00 00 00 00 0d b6 6c 00 06 23 af 13 1a 05 04 fa 05 20 39 01 00 00 00 00 02 b0 00 39 01 00 00 00 00 32 c4 00 00 00 00 00 00 00 00 10 00 00 02 00 00 00 29 00 01 00 00 00 00 00 00 00 00 00 00 00 22 00 00 00 00 11 00 00 0c 00 00 00 00 30 00 00 00 00 00 00 39 01 00 00 00 00 86 cf 64 0b 00 22 00 cd 03 33 04 00 0b 77 01 01 01 02 02 03 03 04 04 04 04 05 00 00 00 3b 00 3b 01 64 01 64 01 64 01 64 01 64 01 64 03 ff 03 ff 03 ff 00 00 00 3b 00 3b 01 64 01 64 01 64 01 64 01 64 01 64 03 ff 03 ff 03 ff 01 62 01 62 01 62 01 62 01 62 01 62 01 62 01 62 01 62 01 62 01 62 01 62 19 19 19 19 19 19 19 19 19 19 19 19 00 00 00 43 00 43 01 98 01 98 06 61 06 61 0f f6 0f f6 0f f6 0f f6 0f f6 19 39 01 00 00 00 00 0d d0 44 44 b2 28 00 28 5a 00 5a 03 0d 01 39 01 00 00 00 00 09 d1 05 00 21 02 24 19 24 2d 39 01 00 00 00 00 15 d3 49 00 00 01 1a 15 00 15 07 0f 77 77 77 37 b2 11 00 a0 3c 9a 39 01 00 00 00 00 1a d7 00 b9 34 00 40 04 00 f0 0f 00 40 00 00 00 00 00 00 19 34 00 40 04 00 f0 0f 39 01 00 00 00 00 34 d8 00 00 00 00 00 00 00 00 00 30 00 30 00 30 00 30 00 30 05 00 00 00 00 00 00 00 00 00 0f 00 0f 00 00 00 00 00 00 00 00 00 00 00 00 00 0f 00 2f 00 0f 00 20 39 01 00 00 00 00 2b df 50 42 58 81 2d 00 00 00 00 00 00 6b 00 00 00 00 00 00 00 00 01 0f ff d4 0e 00 00 00 00 00 00 0f 53 18 00 0f 00 00 00 00 00 00 39 01 00 00 00 00 03 eb 8b 8b 39 01 00 00 00 00 02 f7 01 39 01 00 00 00 00 02 b0 80 39 01 00 00 00 00 0a e4 34 b4 00 00 00 30 04 0c e2 39 01 00 00 00 00 02 e6 00 39 01 00 00 00 00 02 b0 04 39 01 00 00 00 00 03 df 50 40 39 01 00 00 00 00 06 f3 50 00 00 00 00 39 01 00 00 00 00 02 f2 11 39 01 00 00 00 00 06 f3 01 00 00 00 01 39 01 00 00 00 00 03 f4 00 02 39 01 00 00 00 00 02 f2 19 39 01 00 00 00 00 03 df 50 42 39 01 00 00 00 00 02 35 00 39 01 00 00 00 00 05 2a 00 00 04 37 39 01 00 00 00 00 05 2b 00 00 09 23 05 01 00 00 78 00 01 11 05 01 00 00 00 00 01 29];
				qcom,mdss-dsi-off-command = [05 01 00 00 14 00 02 28 00 05 01 00 00 78 00 02 10 00];
				qcom,mdss-dsi-on-command-state = "dsi_lp_mode";
				qcom,mdss-dsi-off-command-state = "dsi_hs_mode";
				qcom,mdss-dsi-h-sync-pulse = <0x0>;
				qcom,compression-mode = "dsc";
				qcom,mdss-dsc-slice-height = <0x14>;
				qcom,mdss-dsc-slice-width = <0x21c>;
				qcom,mdss-dsc-slice-per-pkt = <0x2>;
				qcom,mdss-dsc-bit-per-component = <0x8>;
				qcom,mdss-dsc-bit-per-pixel = <0x8>;
				qcom,mdss-dsc-block-prediction-enable;
				qcom,mdss-dsi-panel-phy-timings = [00 00 00 00 21 1f 06 19 07 02 04 00 00 00];
				qcom,display-topology = <0x1 0x1 0x1>;
				qcom,default-topology-index = <0x0>;
			};

			timing@1 {
				qcom,mdss-dsi-panel-framerate = <0x3c>;
				qcom,mdss-dsi-panel-width = <0x438>;
				qcom,mdss-dsi-panel-height = <0x924>;
				qcom,mdss-dsi-h-front-porch = <0x60>;
				qcom,mdss-dsi-h-back-porch = <0x28>;
				qcom,mdss-dsi-h-pulse-width = <0x20>;
				qcom,mdss-dsi-h-sync-skew = <0x0>;
				qcom,mdss-dsi-v-back-porch = <0x4>;
				qcom,mdss-dsi-v-front-porch = <0x19>;
				qcom,mdss-dsi-v-pulse-width = <0x1>;
				qcom,mdss-dsi-h-left-border = <0x0>;
				qcom,mdss-dsi-h-right-border = <0x0>;
				qcom,mdss-dsi-v-top-border = <0x0>;
				qcom,mdss-dsi-v-bottom-border = <0x0>;
				qcom,mdss-dsi-panel-jitter = <0x4 0x1>;
				qcom,mdss-dsi-timing-switch-command = [39 01 00 00 00 00 34 d8 00 00 00 00 00 00 00 00 00 3a 00 3a 00 3a 00 3a 00 3a 05 00 00 00 00 00 00 00 00 00 0f 00 0f 00 00 00 00 00 00 00 00 00 00 00 00 00 0f 00 2f 00 0f 00 20 39 01 00 00 00 00 02 b0 00 39 01 00 00 00 00 1a c2 09 24 0c 00 00 0c 09 3c 00 09 3c 00 00 00 00 00 00 00 00 00 00 00 30 00 6c];
				qcom,mdss-dsi-on-command = [39 01 00 00 00 00 02 b0 04 39 01 00 00 00 00 03 e8 00 02 39 01 00 00 00 00 03 e4 00 08 39 01 00 00 00 00 03 b4 20 1c 39 01 00 00 00 00 0d b6 6c 00 06 23 af 13 1a 05 04 fa 05 20 39 01 00 00 00 00 02 b0 00 39 01 00 00 00 00 32 c4 00 00 00 00 00 00 00 00 10 00 00 02 00 00 00 29 00 01 00 00 00 00 00 00 00 00 00 00 00 22 00 00 00 00 11 00 00 0c 00 00 00 00 30 00 00 00 00 00 00 39 01 00 00 00 00 86 cf 64 0b 00 22 00 cd 03 33 04 00 0b 77 01 01 01 02 02 03 03 04 04 04 04 05 00 00 00 3b 00 3b 01 64 01 64 01 64 01 64 01 64 01 64 03 ff 03 ff 03 ff 00 00 00 3b 00 3b 01 64 01 64 01 64 01 64 01 64 01 64 03 ff 03 ff 03 ff 01 62 01 62 01 62 01 62 01 62 01 62 01 62 01 62 01 62 01 62 01 62 01 62 19 19 19 19 19 19 19 19 19 19 19 19 00 00 00 43 00 43 01 98 01 98 06 61 06 61 0f f6 0f f6 0f f6 0f f6 0f f6 19 39 01 00 00 00 00 0d d0 44 44 b2 28 00 28 5a 00 5a 03 0d 01 39 01 00 00 00 00 09 d1 05 00 21 02 24 19 24 2d 39 01 00 00 00 00 15 d3 49 00 00 01 1a 15 00 15 07 0f 77 77 77 37 b2 11 00 a0 3c 9a 39 01 00 00 00 00 1a d7 00 b9 34 00 40 04 00 f0 0f 00 40 00 00 00 00 00 00 19 34 00 40 04 00 f0 0f 39 01 00 00 00 00 34 d8 00 00 00 00 00 00 00 00 00 30 00 30 00 30 00 30 00 30 05 00 00 00 00 00 00 00 00 00 0f 00 0f 00 00 00 00 00 00 00 00 00 00 00 00 00 0f 00 2f 00 0f 00 20 39 01 00 00 00 00 2b df 50 42 58 81 2d 00 00 00 00 00 00 6b 00 00 00 00 00 00 00 00 01 0f ff d4 0e 00 00 00 00 00 00 0f 53 18 00 0f 00 00 00 00 00 00 39 01 00 00 00 00 03 eb 8b 8b 39 01 00 00 00 00 02 f7 01 39 01 00 00 00 00 02 b0 80 39 01 00 00 00 00 0a e4 34 b4 00 00 00 30 04 0c e2 39 01 00 00 00 00 02 e6 00 39 01 00 00 00 00 02 b0 04 39 01 00 00 00 00 03 df 50 40 39 01 00 00 00 00 06 f3 50 00 00 00 00 39 01 00 00 00 00 02 f2 11 39 01 00 00 00 00 06 f3 01 00 00 00 01 39 01 00 00 00 00 03 f4 00 02 39 01 00 00 00 00 02 f2 19 39 01 00 00 00 00 03 df 50 42 39 01 00 00 00 00 02 35 00 39 01 00 00 00 00 05 2a 00 00 04 37 39 01 00 00 00 00 05 2b 00 00 09 23 05 01 00 00 78 00 01 11 05 01 00 00 00 00 01 29 39 01 00 00 00 00 0d d0 44 44 b2 28 00 28 5a 00 5a 03 03 01 39 01 00 00 00 00 34 d8 00 00 00 00 00 00 00 00 00 3a 00 3a 00 3a 00 3a 00 3a 05 00 00 00 00 00 00 00 00 00 0f 00 0f 00 00 00 00 00 00 00 00 00 00 00 00 00 0f 00 2f 00 0f 00 20 39 01 00 00 00 00 02 b0 00 39 01 00 00 00 00 1a c2 09 24 0c 00 00 0c 09 3c 00 09 3c 00 00 00 00 00 00 00 00 00 00 00 30 00 6c];
				qcom,mdss-dsi-off-command = [05 01 00 00 14 00 02 28 00 05 01 00 00 78 00 02 10 00];
				qcom,mdss-dsi-on-command-state = "dsi_lp_mode";
				qcom,mdss-dsi-off-command-state = "dsi_hs_mode";
				qcom,mdss-dsi-h-sync-pulse = <0x0>;
				qcom,compression-mode = "dsc";
				qcom,mdss-dsc-slice-height = <0x14>;
				qcom,mdss-dsc-slice-width = <0x21c>;
				qcom,mdss-dsc-slice-per-pkt = <0x2>;
				qcom,mdss-dsc-bit-per-component = <0x8>;
				qcom,mdss-dsc-bit-per-pixel = <0x8>;
				qcom,mdss-dsc-block-prediction-enable;
				qcom,mdss-dsi-panel-phy-timings = [00 00 00 00 1d 13 03 19 02 02 04 00 00 00];
				qcom,display-topology = <0x1 0x1 0x1>;
				qcom,default-topology-index = <0x0>;
			};

			timing@2 {
				qcom,mdss-dsi-panel-framerate = <0x78>;
				qcom,mdss-dsi-panel-width = <0x438>;
				qcom,mdss-dsi-panel-height = <0x924>;
				qcom,mdss-dsi-h-front-porch = <0x60>;
				qcom,mdss-dsi-h-back-porch = <0x28>;
				qcom,mdss-dsi-h-pulse-width = <0x20>;
				qcom,mdss-dsi-h-sync-skew = <0x0>;
				qcom,mdss-dsi-v-back-porch = <0x4>;
				qcom,mdss-dsi-v-front-porch = <0x19>;
				qcom,mdss-dsi-v-pulse-width = <0x1>;
				qcom,mdss-dsi-h-left-border = <0x0>;
				qcom,mdss-dsi-h-right-border = <0x0>;
				qcom,mdss-dsi-v-top-border = <0x0>;
				qcom,mdss-dsi-v-bottom-border = <0x0>;
				qcom,mdss-dsi-panel-jitter = <0x4 0x1>;
				qcom,mdss-dsi-timing-switch-command = [39 01 00 00 00 00 0d d0 44 44 b2 28 00 28 5a 00 5a 03 03 01 39 01 00 00 00 00 02 b0 00 39 01 00 00 00 00 1a c2 09 24 0c 00 00 0c 00 00 00 09 3c 00 00 00 00 00 00 00 00 00 00 00 30 00 6c 39 01 00 00 00 00 34 d8 00 00 00 00 00 00 00 00 00 3a 00 3a 00 3a 00 3a 00 3a 05 00 00 00 00 00 00 00 00 00 0f 00 0f 00 00 00 00 00 00 00 00 00 00 00 00 00 0f 00 2f 00 0f 00 20];
				qcom,mdss-dsi-on-command = [39 01 00 00 00 00 02 b0 04 39 01 00 00 00 00 03 e8 00 02 39 01 00 00 00 00 03 e4 00 08 39 01 00 00 00 00 03 b4 20 1c 39 01 00 00 00 00 0d b6 6c 00 06 23 af 13 1a 05 04 fa 05 20 39 01 00 00 00 00 02 b0 00 39 01 00 00 00 00 32 c4 00 00 00 00 00 00 00 00 10 00 00 02 00 00 00 29 00 01 00 00 00 00 00 00 00 00 00 00 00 22 00 00 00 00 11 00 00 0c 00 00 00 00 30 00 00 00 00 00 00 39 01 00 00 00 00 86 cf 64 0b 00 22 00 cd 03 33 04 00 0b 77 01 01 01 02 02 03 03 04 04 04 04 05 00 00 00 3b 00 3b 01 64 01 64 01 64 01 64 01 64 01 64 03 ff 03 ff 03 ff 00 00 00 3b 00 3b 01 64 01 64 01 64 01 64 01 64 01 64 03 ff 03 ff 03 ff 01 62 01 62 01 62 01 62 01 62 01 62 01 62 01 62 01 62 01 62 01 62 01 62 19 19 19 19 19 19 19 19 19 19 19 19 00 00 00 43 00 43 01 98 01 98 06 61 06 61 0f f6 0f f6 0f f6 0f f6 0f f6 19 39 01 00 00 00 00 0d d0 44 44 b2 28 00 28 5a 00 5a 03 0d 01 39 01 00 00 00 00 09 d1 05 00 21 02 24 19 24 2d 39 01 00 00 00 00 15 d3 49 00 00 01 1a 15 00 15 07 0f 77 77 77 37 b2 11 00 a0 3c 9a 39 01 00 00 00 00 1a d7 00 b9 34 00 40 04 00 f0 0f 00 40 00 00 00 00 00 00 19 34 00 40 04 00 f0 0f 39 01 00 00 00 00 34 d8 00 00 00 00 00 00 00 00 00 30 00 30 00 30 00 30 00 30 05 00 00 00 00 00 00 00 00 00 0f 00 0f 00 00 00 00 00 00 00 00 00 00 00 00 00 0f 00 2f 00 0f 00 20 39 01 00 00 00 00 2b df 50 42 58 81 2d 00 00 00 00 00 00 6b 00 00 00 00 00 00 00 00 01 0f ff d4 0e 00 00 00 00 00 00 0f 53 18 00 0f 00 00 00 00 00 00 39 01 00 00 00 00 03 eb 8b 8b 39 01 00 00 00 00 02 f7 01 39 01 00 00 00 00 02 b0 80 39 01 00 00 00 00 0a e4 34 b4 00 00 00 30 04 0c e2 39 01 00 00 00 00 02 e6 00 39 01 00 00 00 00 02 b0 04 39 01 00 00 00 00 03 df 50 40 39 01 00 00 00 00 06 f3 50 00 00 00 00 39 01 00 00 00 00 02 f2 11 39 01 00 00 00 00 06 f3 01 00 00 00 01 39 01 00 00 00 00 03 f4 00 02 39 01 00 00 00 00 02 f2 19 39 01 00 00 00 00 03 df 50 42 39 01 00 00 00 00 02 35 00 39 01 00 00 00 00 05 2a 00 00 04 37 39 01 00 00 00 00 05 2b 00 00 09 23 05 01 00 00 78 00 01 11 05 01 00 00 00 00 01 29 39 01 00 00 00 00 0d d0 44 44 b2 28 00 28 5a 00 5a 03 03 01 39 01 00 00 00 00 34 d8 00 00 00 00 00 00 00 00 00 3a 00 3a 00 3a 00 3a 00 3a 05 00 00 00 00 00 00 00 00 00 0f 00 0f 00 00 00 00 00 00 00 00 00 00 00 00 00 0f 00 2f 00 0f 00 20];
				qcom,mdss-dsi-off-command = [05 01 00 00 14 00 02 28 00 05 01 00 00 78 00 02 10 00];
				qcom,mdss-dsi-on-command-state = "dsi_lp_mode";
				qcom,mdss-dsi-off-command-state = "dsi_hs_mode";
				qcom,mdss-dsi-h-sync-pulse = <0x0>;
				qcom,compression-mode = "dsc";
				qcom,mdss-dsc-slice-height = <0x14>;
				qcom,mdss-dsc-slice-width = <0x21c>;
				qcom,mdss-dsc-slice-per-pkt = <0x2>;
				qcom,mdss-dsc-bit-per-component = <0x8>;
				qcom,mdss-dsc-bit-per-pixel = <0x8>;
				qcom,mdss-dsc-block-prediction-enable;
				qcom,mdss-dsi-panel-phy-timings = [00 00 00 00 20 1b 05 19 06 02 04 00 00 00];
				qcom,display-topology = <0x1 0x1 0x1>;
				qcom,default-topology-index = <0x0>;
			};
		};
	};

	dsi_r66451_amoled_144hz_video_cphy: qcom,mdss_dsi_r66451_fhd_plus_cphy_144hz_vid {
		qcom,mdss-dsi-panel-name = "r66451 amoled video mode dsi visionox panel with DSC";
		qcom,mdss-dsi-panel-type = "dsi_video_mode";
		qcom,mdss-dsi-panel-physical-type = "oled";
		qcom,dsi-ctrl-num = <0x0>;
		qcom,dsi-phy-num = <0x0>;
		qcom,mdss-dsi-virtual-channel-id = <0x0>;
		qcom,mdss-dsi-stream = <0x0>;
		qcom,mdss-dsi-bpp = <0x18>;
		qcom,mdss-dsi-border-color = <0x0>;
		qcom,mdss-dsi-traffic-mode = "non_burst_sync_event";
		qcom,mdss-dsi-bllp-eof-power-mode;
		qcom,mdss-dsi-bllp-power-mode;
		qcom,mdss-dsi-lane-0-state;
		qcom,mdss-dsi-lane-1-state;
		qcom,mdss-dsi-lane-2-state;
		qcom,mdss-dsi-dma-trigger = "trigger_sw";
		qcom,mdss-dsi-mdp-trigger = "none";
		qcom,mdss-dsi-reset-sequence = <0x1 0xa 0x0 0xa 0x1 0xa>;
		qcom,adjust-timer-wakeup-ms = <0x1>;
		qcom,panel-cphy-mode;
		qcom,dsi-select-clocks = "mux_byte_clk0", "mux_pixel_clk0", "cphy_byte_clk0", "cphy_pixel_clk0";
		qcom,dsi-supported-dfps-list = <0x90 0x78 0x5a 0x3c>;
		qcom,mdss-dsi-pan-enable-dynamic-fps;
		qcom,mdss-dsi-pan-fps-update = "dfps_immediate_porch_mode_vfp";
		qcom,esd-check-enabled;
		qcom,mdss-dsi-panel-status-check-mode = "reg_read";
		qcom,mdss-dsi-panel-status-command = <0x6010001 0x10a>;
		qcom,mdss-dsi-panel-status-command-state = "dsi_lp_mode";
		qcom,mdss-dsi-panel-status-value = <0x1c>;
		qcom,mdss-dsi-panel-status-read-length = <0x1>;

		qcom,mdss-dsi-display-timings {

			timing@0 {
				qcom,mdss-dsi-panel-framerate = <0x90>;
				qcom,mdss-dsi-panel-width = <0x438>;
				qcom,mdss-dsi-panel-height = <0x924>;
				qcom,mdss-dsi-h-front-porch = <0x60>;
				qcom,mdss-dsi-h-back-porch = <0x28>;
				qcom,mdss-dsi-h-pulse-width = <0x20>;
				qcom,mdss-dsi-h-sync-skew = <0x0>;
				qcom,mdss-dsi-v-back-porch = <0x4>;
				qcom,mdss-dsi-v-front-porch = <0x19>;
				qcom,mdss-dsi-v-pulse-width = <0x1>;
				qcom,mdss-dsi-h-left-border = <0x0>;
				qcom,mdss-dsi-h-right-border = <0x0>;
				qcom,mdss-dsi-v-top-border = <0x0>;
				qcom,mdss-dsi-v-bottom-border = <0x0>;
				qcom,mdss-dsi-on-command = [39 01 00 00 00 00 02 b0 00 39 01 00 00 00 00 02 b3 01 39 01 00 00 00 00 02 b0 04 39 01 00 00 00 00 03 e8 00 02 39 01 00 00 00 00 03 e4 00 08 39 01 00 00 00 00 03 b4 20 1c 39 01 00 00 00 00 0d b6 6c 00 06 23 af 13 1a 05 04 fa 05 20 39 01 00 00 00 00 02 b0 00 39 01 00 00 00 00 32 c4 00 00 00 00 00 00 00 00 10 00 00 02 00 00 00 29 00 01 00 00 00 00 00 00 00 00 00 00 00 22 00 00 00 00 11 00 00 0c 00 00 00 00 30 00 00 00 00 00 00 39 01 00 00 00 00 86 cf 64 0b 00 22 00 cd 03 33 04 00 0b 77 01 01 01 02 02 03 03 04 04 04 04 05 00 00 00 3b 00 3b 01 64 01 64 01 64 01 64 01 64 01 64 03 ff 03 ff 03 ff 00 00 00 3b 00 3b 01 64 01 64 01 64 01 64 01 64 01 64 03 ff 03 ff 03 ff 01 62 01 62 01 62 01 62 01 62 01 62 01 62 01 62 01 62 01 62 01 62 01 62 19 19 19 19 19 19 19 19 19 19 19 19 00 00 00 43 00 43 01 98 01 98 06 61 06 61 0f f6 0f f6 0f f6 0f f6 0f f6 19 39 01 00 00 00 00 0d d0 44 44 b2 28 00 28 5a 00 5a 03 0d 01 39 01 00 00 00 00 09 d1 05 00 21 02 24 19 24 2d 39 01 00 00 00 00 15 d3 49 00 00 01 1a 15 00 15 07 0f 77 77 77 37 b2 11 00 a0 3c 9a 39 01 00 00 00 00 1a d7 00 b9 34 00 40 04 00 f0 0f 00 40 00 00 00 00 00 00 19 34 00 40 04 00 f0 0f 39 01 00 00 00 00 34 d8 00 00 00 00 00 00 00 00 00 30 00 30 00 30 00 30 00 30 05 00 00 00 00 00 00 00 00 00 0f 00 0f 00 00 00 00 00 00 00 00 00 00 00 00 00 0f 00 2f 00 0f 00 20 39 01 00 00 00 00 2b df 50 42 58 81 2d 00 00 00 00 00 00 6b 00 00 00 00 00 00 00 00 01 0f ff d4 0e 00 00 00 00 00 00 0f 53 18 00 0f 00 00 00 00 00 00 39 01 00 00 00 00 03 eb 8b 8b 39 01 00 00 00 00 02 f7 01 39 01 00 00 00 00 02 b0 80 39 01 00 00 00 00 0a e4 34 b4 00 00 00 30 04 0c e2 39 01 00 00 00 00 02 e6 00 39 01 00 00 00 00 02 b0 04 39 01 00 00 00 00 03 df 50 40 39 01 00 00 00 00 06 f3 50 00 00 00 00 39 01 00 00 00 00 02 f2 11 39 01 00 00 00 00 06 f3 01 00 00 00 01 39 01 00 00 00 00 03 f4 00 02 39 01 00 00 00 00 02 f2 19 39 01 00 00 00 00 03 df 50 42 39 01 00 00 00 00 05 2a 00 00 04 37 39 01 00 00 00 00 05 2b 00 00 09 23 05 01 00 00 78 00 01 11 05 01 00 00 00 00 01 29];
				qcom,mdss-dsi-off-command = [05 01 00 00 14 00 02 28 00 05 01 00 00 78 00 02 10 00];
				qcom,mdss-dsi-on-command-state = "dsi_lp_mode";
				qcom,mdss-dsi-off-command-state = "dsi_hs_mode";
				qcom,mdss-dsi-h-sync-pulse = <0x0>;
				qcom,compression-mode = "dsc";
				qcom,mdss-dsc-slice-height = <0x14>;
				qcom,mdss-dsc-slice-width = <0x21c>;
				qcom,mdss-dsc-slice-per-pkt = <0x2>;
				qcom,mdss-dsc-bit-per-component = <0x8>;
				qcom,mdss-dsc-bit-per-pixel = <0x8>;
				qcom,mdss-dsc-block-prediction-enable;
				qcom,mdss-dsi-panel-phy-timings = [00 00 00 00 1e 17 04 19 03 02 04 00 00 00];
				qcom,display-topology = <0x1 0x1 0x1>;
				qcom,default-topology-index = <0x0>;
			};
		};
	};

	dsi_sim_vid: qcom,mdss_dsi_sim_video {
		qcom,mdss-dsi-panel-name = "Simulator video mode dsi panel";
		qcom,mdss-dsi-panel-type = "dsi_video_mode";
		qcom,dsi-ctrl-num = <0x0>;
		qcom,dsi-phy-num = <0x0>;
		qcom,mdss-dsi-virtual-channel-id = <0x0>;
		qcom,mdss-dsi-stream = <0x0>;
		qcom,mdss-dsi-bpp = <0x18>;
		qcom,mdss-dsi-underflow-color = <0xff>;
		qcom,mdss-dsi-border-color = <0x0>;
		qcom,mdss-dsi-panel-hdr-enabled;
		qcom,mdss-dsi-panel-hdr-color-primaries = <0x38a4 0x3c8c 0x7d00 0x4268 0x3c8c 0x7530 0x1f40 0xbb8>;
		qcom,mdss-dsi-panel-peak-brightness = <0x401640>;
		qcom,mdss-dsi-panel-blackness-level = <0xc9e>;
		qcom,mdss-dsi-traffic-mode = "non_burst_sync_event";
		qcom,mdss-dsi-bllp-eof-power-mode;
		qcom,mdss-dsi-bllp-power-mode;
		qcom,mdss-dsi-lane-0-state;
		qcom,mdss-dsi-lane-1-state;
		qcom,mdss-dsi-lane-2-state;
		qcom,mdss-dsi-lane-3-state;
		qcom,mdss-dsi-t-clk-post = <0x4>;
		qcom,mdss-dsi-t-clk-pre = <0x1b>;
		qcom,mdss-dsi-dma-trigger = "trigger_sw";
		qcom,mdss-dsi-mdp-trigger = "none";
		qcom,mdss-dsi-reset-sequence = <0x1 0x0 0x0 0x0 0x1 0x0>;
		qcom,panel-ack-disabled;
		qcom,dsi-select-clocks = "mux_byte_clk0", "mux_pixel_clk0";
		qcom,panel-supply-entries = <&dsi_panel_pwr_supply_labibb>;
		qcom,mdss-dsi-bl-pmic-control-type = "bl_ctrl_dcs";
		qcom,platform-reset-gpio = <&tlmm 0x2c 0x0>;

		qcom,mdss-dsi-display-timings {

			timing@0 {
				qcom,mdss-dsi-panel-width = <0x280>;
				qcom,mdss-dsi-panel-height = <0x1e0>;
				qcom,mdss-dsi-h-front-porch = <0x8>;
				qcom,mdss-dsi-h-back-porch = <0x8>;
				qcom,mdss-dsi-h-pulse-width = <0x8>;
				qcom,mdss-dsi-h-sync-skew = <0x0>;
				qcom,mdss-dsi-v-back-porch = <0x6>;
				qcom,mdss-dsi-v-front-porch = <0x6>;
				qcom,mdss-dsi-v-pulse-width = <0x2>;
				qcom,mdss-dsi-h-left-border = <0x0>;
				qcom,mdss-dsi-h-right-border = <0x0>;
				qcom,mdss-dsi-v-top-border = <0x0>;
				qcom,mdss-dsi-v-bottom-border = <0x0>;
				qcom,mdss-dsi-panel-framerate = <0x3c>;
				qcom,mdss-dsi-panel-timings = <0x0 0x0 0x0>;
				qcom,mdss-dsi-on-command = [32 01 00 00 00 00 02 00 00];
				qcom,mdss-dsi-off-command = [22 01 00 00 00 00 02 00 00];
				qcom,mdss-dsi-on-command-state = "dsi_lp_mode";
				qcom,mdss-dsi-off-command-state = "dsi_lp_mode";
				qcom,mdss-dsi-h-sync-pulse = <0x0>;
				qcom,mdss-dsi-panel-phy-timings = [01 05 01 01 03 03 01 01 01 02 04 00 06 06];
				qcom,display-topology = <0x1 0x0 0x1>;
				qcom,default-topology-index = <0x0>;
			};
		};
	};
};

&soc {

	dsi_panel_pwr_supply: dsi_panel_pwr_supply {
		#address-cells = <0x1>;
		#size-cells = <0x0>;

		qcom,panel-supply-entry@0 {
			reg = <0x0>;
			qcom,supply-name = "vddio";
			qcom,supply-min-voltage = <0x1bc560>;
			qcom,supply-max-voltage = <0x1bc560>;
			qcom,supply-enable-load = <0xed1c>;
			qcom,supply-disable-load = <0x50>;
			qcom,supply-post-on-sleep = <0x14>;
		};

		qcom,panel-supply-entry@1 {
			reg = <0x1>;
			qcom,supply-name = "vdd";
			qcom,supply-min-voltage = <0x2dc6c0>;
			qcom,supply-max-voltage = <0x2dc6c0>;
			qcom,supply-enable-load = <0x7530>;
			qcom,supply-disable-load = <0x0>;
			qcom,supply-post-on-sleep = <0x0>;
		};

		qcom,panel-supply-entry@2 {
			reg = <0x2>;
			qcom,supply-name = "lab";
			qcom,supply-min-voltage = <0x4630c0>;
			qcom,supply-max-voltage = <0x5b8d80>;
			qcom,supply-enable-load = <0x0>;
			qcom,supply-disable-load = <0x0>;
		};

		qcom,panel-supply-entry@3 {
			reg = <0x3>;
			qcom,supply-name = "ibb";
			qcom,supply-min-voltage = <0x4630c0>;
			qcom,supply-max-voltage = <0x5b8d80>;
			qcom,supply-enable-load = <0x0>;
			qcom,supply-disable-load = <0x0>;
			qcom,supply-post-on-sleep = <0x14>;
		};
	};

	dsi_panel_pwr_supply_labibb: dsi_panel_pwr_supply_labibb {
		#address-cells = <0x1>;
		#size-cells = <0x0>;

		qcom,panel-supply-entry@0 {
			reg = <0x0>;
			qcom,supply-name = "vddio";
			qcom,supply-min-voltage = <0x1b7740>;
			qcom,supply-max-voltage = <0x1b7740>;
			qcom,supply-enable-load = <0xf230>;
			qcom,supply-disable-load = <0x50>;
			qcom,supply-post-on-sleep = <0x14>;
		};

		qcom,panel-supply-entry@1 {
			reg = <0x1>;
			qcom,supply-name = "lab";
			qcom,supply-min-voltage = <0x557300>;
			qcom,supply-max-voltage = <0x5b8d80>;
			qcom,supply-enable-load = <0x0>;
			qcom,supply-disable-load = <0x0>;
		};

		qcom,panel-supply-entry@2 {
			reg = <0x2>;
			qcom,supply-name = "ibb";
			qcom,supply-min-voltage = <0x557300>;
			qcom,supply-max-voltage = <0x5b8d80>;
			qcom,supply-enable-load = <0x0>;
			qcom,supply-disable-load = <0x0>;
			qcom,supply-post-on-sleep = <0x14>;
		};
	};

	dsi_panel_pwr_supply_amoled: dsi_panel_pwr_supply_amoled {
		#address-cells = <0x1>;
		#size-cells = <0x0>;

		qcom,panel-supply-entry@0 {
			reg = <0x0>;
			qcom,supply-name = "vddio";
			qcom,supply-min-voltage = <0x1b7740>;
			qcom,supply-max-voltage = <0x1b7740>;
			qcom,supply-enable-load = <0xed1c>;
			qcom,supply-disable-load = <0x50>;
			qcom,supply-post-on-sleep = <0x14>;
		};

		qcom,panel-supply-entry@1 {
			reg = <0x1>;
			qcom,supply-name = "vdd";
			qcom,supply-min-voltage = <0x2dc6c0>;
			qcom,supply-max-voltage = <0x2dc6c0>;
			qcom,supply-enable-load = <0x7530>;
			qcom,supply-disable-load = <0x0>;
			qcom,supply-post-on-sleep = <0x0>;
		};
	};

	dsi_panel_pwr_supply_no_labibb: dsi_panel_pwr_supply_no_labibb {
		#address-cells = <0x1>;
		#size-cells = <0x0>;

		qcom,panel-supply-entry@0 {
			reg = <0x0>;
			qcom,supply-name = "vddio";
			qcom,supply-min-voltage = <0x1b7740>;
			qcom,supply-max-voltage = <0x1b7740>;
			qcom,supply-enable-load = <0xf230>;
			qcom,supply-disable-load = <0x50>;
			qcom,supply-post-on-sleep = <0x14>;
		};
	};
};

